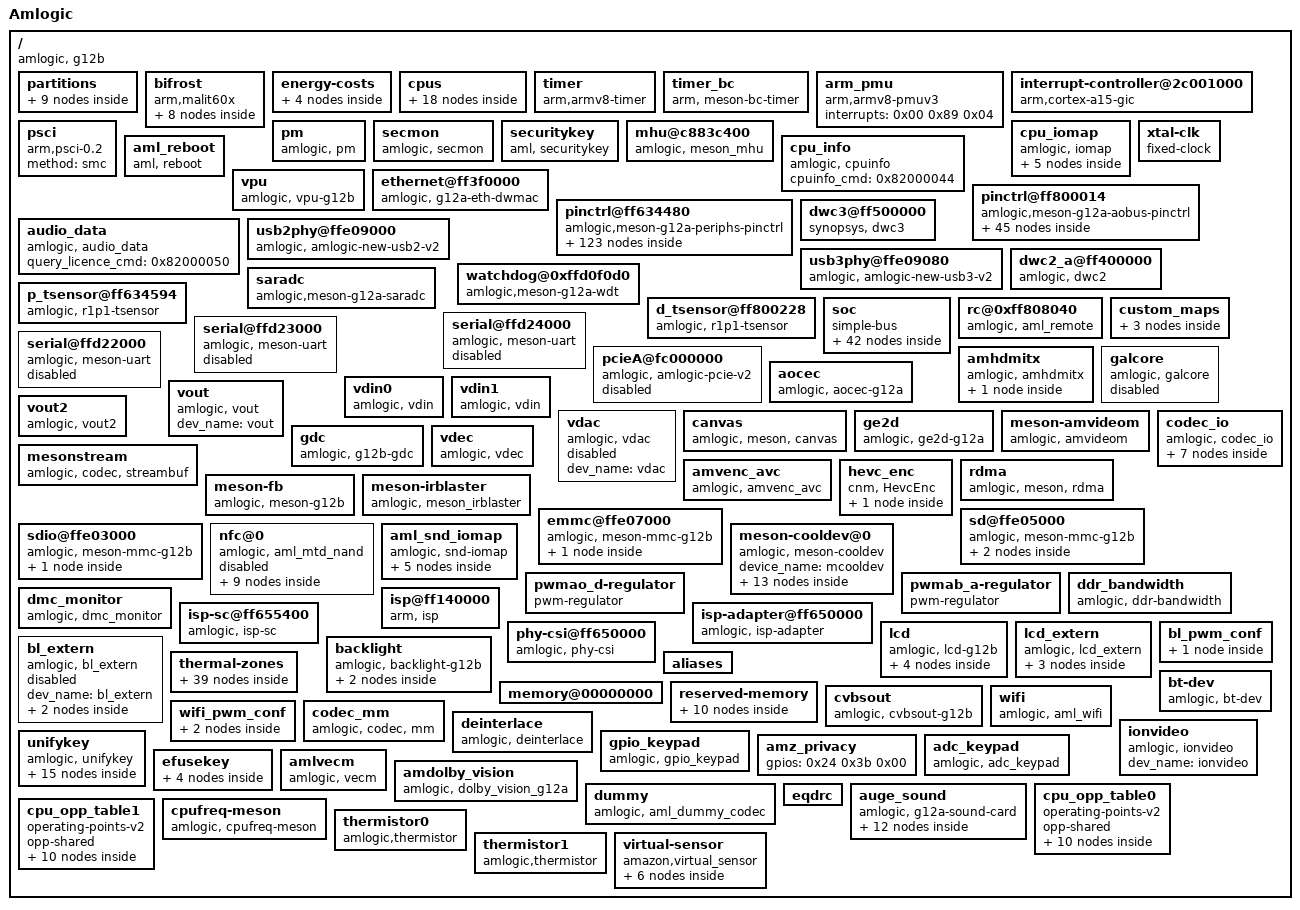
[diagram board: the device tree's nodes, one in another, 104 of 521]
/dts-v1/;

/ {
	model = "Amlogic";
	amlogic-dt-id = "g12b_ravenproto_2g";
	compatible = "amlogic, g12b";
	interrupt-parent = <0x01>;
	#address-cells = <0x02>;
	#size-cells = <0x02>;

	partitions {
		parts = <0x09>;
		part-0 = <0x02>;
		part-1 = <0x03>;
		part-2 = <0x04>;
		part-3 = <0x05>;
		part-4 = <0x06>;
		part-5 = <0x07>;
		part-6 = <0x08>;
		part-7 = <0x09>;
		part-8 = <0x0a>;

		boot {
			pname = "boot";
			size = <0x00 0x1000000>;
			mask = <0x01>;
			linux,phandle = <0x02>;
			phandle = <0x02>;
		};

		recovery {
			pname = "recovery";
			size = <0x00 0x1000000>;
			mask = <0x01>;
			linux,phandle = <0x03>;
			phandle = <0x03>;
		};

		logo {
			pname = "logo";
			size = <0x00 0x400000>;
			mask = <0x01>;
			linux,phandle = <0x04>;
			phandle = <0x04>;
		};

		tee {
			pname = "tee";
			size = <0x00 0x800000>;
			mask = <0x01>;
			linux,phandle = <0x05>;
			phandle = <0x05>;
		};

		system {
			pname = "system";
			size = <0x00 0x4b000000>;
			mask = <0x01>;
			linux,phandle = <0x06>;
			phandle = <0x06>;
		};

		misc {
			pname = "misc";
			size = <0x00 0x100000>;
			mask = <0x02>;
			linux,phandle = <0x07>;
			phandle = <0x07>;
		};

		cache {
			pname = "cache";
			size = <0x00 0x20000000>;
			mask = <0x02>;
			linux,phandle = <0x08>;
			phandle = <0x08>;
		};

		vendor {
			pname = "vendor";
			size = <0x00 0x10000000>;
			mask = <0x01>;
			linux,phandle = <0x09>;
			phandle = <0x09>;
		};

		data {
			pname = "data";
			size = <0xffffffff 0xffffffff>;
			mask = <0x04>;
			linux,phandle = <0x0a>;
			phandle = <0x0a>;
		};
	};

	bifrost {
		compatible = "arm,malit60x\0arm,malit6xx\0arm,mali-midgard";
		#cooling-cells = <0x02>;
		reg = <0x00 0xffe40000 0x00 0x4000 0x00 0xffd01000 0x00 0x1000 0x00 0xff800000 0x00 0x1000 0x00 0xff63c000 0x00 0x1000 0x00 0xffd01000 0x00 0x1000>;
		interrupt-parent = <0x01>;
		interrupts = <0x00 0xa0 0x04 0x00 0xa1 0x04 0x00 0xa2 0x04>;
		interrupt-names = "GPU\0MMU\0JOB";
		num_of_pp = <0x02>;
		sc_mpp = <0x01>;
		clocks = <0x0b 0x83 0x0b 0x07>;
		clock-names = "gpu_mux\0gp0_pll";
		tbl = <0x0c 0x0d 0x0e 0x0f 0x10 0x10>;
		system-coherency = <0x00>;

		clk125_cfg {
			clk_freq = <0x7735940>;
			clk_parent = "fclk_div4";
			clkp_freq = <0x1dcd6500>;
			clk_reg = <0xa03>;
			voltage = <0x47e>;
			keep_count = <0x05>;
			threshold = <0x1e 0x78>;
		};

		dvfs250_cfg {
			clk_freq = <0xee6b280>;
			clk_parent = "fclk_div4";
			clkp_freq = <0x1dcd6500>;
			clk_reg = <0xa01>;
			voltage = <0x47e>;
			keep_count = <0x05>;
			threshold = <0x50 0xaa>;
		};

		dvfs285_cfg {
			clk_freq = <0x1107a76d>;
			clk_parent = "fclk_div7";
			clkp_freq = <0x1107a76d>;
			clk_reg = <0xe00>;
			voltage = <0x47e>;
			keep_count = <0x05>;
			threshold = <0x64 0xbe>;
			linux,phandle = <0x0c>;
			phandle = <0x0c>;
		};

		dvfs400_cfg {
			clk_freq = <0x17d78400>;
			clk_parent = "fclk_div5";
			clkp_freq = <0x17d78400>;
			clk_reg = <0xc00>;
			voltage = <0x47e>;
			keep_count = <0x05>;
			threshold = <0x98 0xcf>;
			linux,phandle = <0x0d>;
			phandle = <0x0d>;
		};

		dvfs500_cfg {
			clk_freq = <0x1dcd6500>;
			clk_parent = "fclk_div4";
			clkp_freq = <0x1dcd6500>;
			clk_reg = <0xa00>;
			voltage = <0x47e>;
			keep_count = <0x05>;
			threshold = <0xb4 0xdc>;
			linux,phandle = <0x0e>;
			phandle = <0x0e>;
		};

		dvfs666_cfg {
			clk_freq = <0x27bc86aa>;
			clk_parent = "fclk_div3";
			clkp_freq = <0x27bc86aa>;
			clk_reg = <0x800>;
			voltage = <0x47e>;
			keep_count = <0x05>;
			threshold = <0xd2 0xec>;
			linux,phandle = <0x0f>;
			phandle = <0x0f>;
		};

		dvfs800_cfg {
			clk_freq = <0x2faf0800>;
			clk_parent = "fclk_div2p5";
			clkp_freq = <0x2faf0800>;
			clk_reg = <0x600>;
			voltage = <0x47e>;
			keep_count = <0x05>;
			threshold = <0xe6 0xff>;
			linux,phandle = <0x10>;
			phandle = <0x10>;
		};

		dvfs850_cfg {
			clk_freq = <0x326cef80>;
			clk_parent = "gp0_pll";
			clkp_freq = <0x326cef80>;
			clk_reg = <0x200>;
			voltage = <0x47e>;
			keep_count = <0x05>;
			threshold = <0xe6 0xff>;
		};
	};

	energy-costs {

		core-cost0 {
			busy-cost-data = <0x36 0x11 0x87 0x6e 0x10e 0xca 0x168 0x108 0x21c 0x18c 0x288 0x1d6 0x2f3 0x22d 0x330 0x26c 0x364 0x2bb 0x398 0x2f7>;
			idle-cost-data = <0x05 0x00 0x00>;
			linux,phandle = <0x1b>;
			phandle = <0x1b>;
		};

		core-cost1 {
			busy-cost-data = <0x21 0x04 0x53 0x17 0xa6 0x29 0xdd 0x36 0x14c 0x4e 0x18f 0x5c 0x1d1 0x0b 0x1f7 0x87 0x217 0xa2 0x237 0xb8 0x277 0x117>;
			idle-cost-data = <0x03 0x00 0x00>;
			linux,phandle = <0x17>;
			phandle = <0x17>;
		};

		cluster-cost0 {
			busy-cost-data = <0x36 0x11 0x87 0x14 0x10e 0x19 0x168 0x1b 0x21c 0x23 0x288 0x28 0x2f3 0x31 0x330 0x39 0x364 0x36 0x398 0x40>;
			idle-cost-data = <0x0a 0x0a 0x00>;
			linux,phandle = <0x1c>;
			phandle = <0x1c>;
		};

		cluster-cost1 {
			busy-cost-data = <0x21 0x07 0x53 0x08 0xa6 0x09 0xdd 0x0a 0x14c 0x0d 0x18f 0x0f 0x1d1 0x13 0x1f7 0x17 0x217 0x1a 0x237 0x1f 0x277 0x2a>;
			idle-cost-data = <0x06 0x06 0x00>;
			linux,phandle = <0x18>;
			phandle = <0x18>;
		};
	};

	cpus {
		#address-cells = <0x02>;
		#size-cells = <0x00>;

		cpu-map {

			cluster0 {

				core0 {
					cpu = <0x11>;
				};

				core1 {
					cpu = <0x12>;
				};
			};

			cluster1 {

				core0 {
					cpu = <0x13>;
				};

				core1 {
					cpu = <0x14>;
				};

				core2 {
					cpu = <0x15>;
				};

				core3 {
					cpu = <0x16>;
				};
			};
		};

		cpu@0 {
			device_type = "cpu";
			compatible = "arm,cortex-a53\0arm,armv8";
			reg = <0x00 0x00>;
			enable-method = "psci";
			sched-energy-costs = <0x17 0x18>;
			clocks = <0x0b 0x17 0x0b 0x16 0x0b 0xe7>;
			clock-names = "core_clk\0low_freq_clk_parent\0high_freq_clk_parent";
			operating-points-v2 = <0x19>;
			cpu-supply = <0x1a>;
			voltage-tolerance = <0x00>;
			clock-latency = <0xc350>;
			linux,phandle = <0x11>;
			phandle = <0x11>;
		};

		cpu@1 {
			device_type = "cpu";
			compatible = "arm,cortex-a53\0arm,armv8";
			reg = <0x00 0x01>;
			enable-method = "psci";
			sched-energy-costs = <0x17 0x18>;
			clocks = <0x0b 0x17 0x0b 0x16 0x0b 0xe7>;
			clock-names = "core_clk\0low_freq_clk_parent\0high_freq_clk_parent";
			operating-points-v2 = <0x19>;
			cpu-supply = <0x1a>;
			voltage-tolerance = <0x00>;
			clock-latency = <0xc350>;
			linux,phandle = <0x12>;
			phandle = <0x12>;
		};

		cpu@100 {
			device_type = "cpu";
			compatible = "arm,cortex-a73\0arm,armv8";
			reg = <0x00 0x100>;
			enable-method = "psci";
			sched-energy-costs = <0x1b 0x1c>;
			clocks = <0x0b 0xd7 0x0b 0xd6 0x0b 0x00>;
			clock-names = "core_clk\0low_freq_clk_parent\0high_freq_clk_parent";
			operating-points-v2 = <0x1d>;
			cpu-supply = <0x1e>;
			voltage-tolerance = <0x00>;
			clock-latency = <0xc350>;
			linux,phandle = <0x13>;
			phandle = <0x13>;
		};

		cpu@101 {
			device_type = "cpu";
			compatible = "arm,cortex-a73\0arm,armv8";
			reg = <0x00 0x101>;
			enable-method = "psci";
			sched-energy-costs = <0x1b 0x1c>;
			clocks = <0x0b 0xd7 0x0b 0xd6 0x0b 0x00>;
			clock-names = "core_clk\0low_freq_clk_parent\0high_freq_clk_parent";
			operating-points-v2 = <0x1d>;
			cpu-supply = <0x1e>;
			voltage-tolerance = <0x00>;
			clock-latency = <0xc350>;
			linux,phandle = <0x14>;
			phandle = <0x14>;
		};

		cpu@102 {
			device_type = "cpu";
			compatible = "arm,cortex-a73\0arm,armv8";
			reg = <0x00 0x102>;
			enable-method = "psci";
			sched-energy-costs = <0x1b 0x1c>;
			clocks = <0x0b 0xd7 0x0b 0xd6 0x0b 0x00>;
			clock-names = "core_clk\0low_freq_clk_parent\0high_freq_clk_parent";
			operating-points-v2 = <0x1d>;
			cpu-supply = <0x1e>;
			voltage-tolerance = <0x00>;
			clock-latency = <0xc350>;
			linux,phandle = <0x15>;
			phandle = <0x15>;
		};

		cpu@103 {
			device_type = "cpu";
			compatible = "arm,cortex-a73\0arm,armv8";
			reg = <0x00 0x103>;
			enable-method = "psci";
			sched-energy-costs = <0x1b 0x1c>;
			clocks = <0x0b 0xd7 0x0b 0xd6 0x0b 0x00>;
			clock-names = "core_clk\0low_freq_clk_parent\0high_freq_clk_parent";
			operating-points-v2 = <0x1d>;
			cpu-supply = <0x1e>;
			voltage-tolerance = <0x00>;
			clock-latency = <0xc350>;
			linux,phandle = <0x16>;
			phandle = <0x16>;
		};

		idle-states {
			entry-method = "arm,psci";

			cpu-sleep-0 {
				compatible = "arm,idle-state";
				arm,psci-suspend-param = <0x10000>;
				local-timer-stop;
				entry-latency-us = <0x1f40>;
				exit-latency-us = <0x1f40>;
				min-residency-us = <0x4e20>;
			};

			cluster-sleep-0 {
				compatible = "arm,idle-state";
				arm,psci-suspend-param = <0x1010000>;
				local-timer-stop;
				entry-latency-us = <0x2328>;
				exit-latency-us = <0x2328>;
				min-residency-us = <0x61a8>;
			};
		};
	};

	timer {
		compatible = "arm,armv8-timer";
		interrupts = <0x01 0x0d 0xff08 0x01 0x0e 0xff08 0x01 0x0b 0xff08 0x01 0x0a 0xff08>;
	};

	timer_bc {
		compatible = "arm, meson-bc-timer";
		reg = <0x00 0xffd0f190 0x00 0x04 0x00 0xffd0f194 0x00 0x04>;
		timer_name = "Meson TimerF";
		clockevent-rating = <0x12c>;
		clockevent-shift = <0x14>;
		clockevent-features = <0x23>;
		interrupts = <0x00 0x3c 0x01>;
		bit_enable = <0x10>;
		bit_mode = <0x0c>;
		bit_resolution = <0x00>;
	};

	arm_pmu {
		compatible = "arm,armv8-pmuv3";
		interrupts = <0x00 0x89 0x04>;
	};

	interrupt-controller@2c001000 {
		compatible = "arm,cortex-a15-gic\0arm,cortex-a9-gic";
		#interrupt-cells = <0x03>;
		#address-cells = <0x00>;
		interrupt-controller;
		reg = <0x00 0xffc01000 0x00 0x1000 0x00 0xffc02000 0x00 0x100>;
		interrupts = <0x01 0x09 0xf04>;
		linux,phandle = <0x01>;
		phandle = <0x01>;
	};

	psci {
		compatible = "arm,psci-0.2";
		method = "smc";
	};

	pm {
		compatible = "amlogic, pm";
		status = "okay";
		device_name = "aml_pm";
		reg = <0x00 0xff8000a8 0x00 0x04 0x00 0xff80023c 0x00 0x04>;
	};

	secmon {
		compatible = "amlogic, secmon";
		memory-region = <0x1f>;
		in_base_func = <0x82000020>;
		out_base_func = <0x82000021>;
		reserve_mem_size = <0x2300000>;
	};

	securitykey {
		compatible = "aml, securitykey";
		storage_query = <0x82000060>;
		storage_read = <0x82000061>;
		storage_write = <0x82000062>;
		storage_tell = <0x82000063>;
		storage_verify = <0x82000064>;
		storage_status = <0x82000065>;
		storage_list = <0x82000067>;
		storage_remove = <0x82000068>;
		storage_in_func = <0x82000023>;
		storage_out_func = <0x82000024>;
		storage_block_func = <0x82000025>;
		storage_size_func = <0x82000027>;
		storage_set_enctype = <0x8200006a>;
		storage_get_enctype = <0x8200006b>;
		storage_version = <0x8200006c>;
	};

	mhu@c883c400 {
		compatible = "amlogic, meson_mhu";
		reg = <0x00 0xff63c400 0x00 0x4c 0x00 0xfffe7000 0x00 0x800>;
		interrupts = <0x00 0xd1 0x01 0x00 0xd2 0x01>;
		#mbox-cells = <0x01>;
		mbox-names = "cpu_to_scp_low\0cpu_to_scp_high";
		mboxes = <0x20 0x00 0x20 0x01>;
		linux,phandle = <0x20>;
		phandle = <0x20>;
	};

	cpu_iomap {
		compatible = "amlogic, iomap";
		#address-cells = <0x02>;
		#size-cells = <0x02>;
		ranges;

		io_cbus_base {
			reg = <0x00 0xffd00000 0x00 0x26000>;
		};

		io_apb_base {
			reg = <0x00 0xffe01000 0x00 0x7f000>;
		};

		io_aobus_base {
			reg = <0x00 0xff800000 0x00 0xb000>;
		};

		io_vapb_base {
			reg = <0x00 0xff900000 0x00 0x50000>;
		};

		io_hiu_base {
			reg = <0x00 0xff63c000 0x00 0x2000>;
		};
	};

	xtal-clk {
		compatible = "fixed-clock";
		clock-frequency = <0x16e3600>;
		clock-output-names = "xtal";
		#clock-cells = <0x00>;
		linux,phandle = <0x25>;
		phandle = <0x25>;
	};

	cpu_info {
		compatible = "amlogic, cpuinfo";
		status = "okay";
		cpuinfo_cmd = <0x82000044>;
	};

	aml_reboot {
		compatible = "aml, reboot";
		sys_reset = <0x84000009>;
		sys_poweroff = <0x84000008>;
	};

	vpu {
		compatible = "amlogic, vpu-g12b";
		dev_name = "vpu";
		status = "okay";
		clocks = <0x0b 0x95 0x0b 0x4c 0x0b 0x87 0x0b 0x8b 0x0b 0x8c>;
		clock-names = "vapb_clk\0vpu_intr_gate\0vpu_clk0\0vpu_clk1\0vpu_clk";
		clk_level = <0x07>;
	};

	ethernet@ff3f0000 {
		compatible = "amlogic, g12a-eth-dwmac\0snps,dwmac";
		reg = <0x00 0xff3f0000 0x00 0x10000 0x00 0xff634540 0x00 0x08 0x00 0xff64c000 0x00 0xa0>;
		reg-names = "eth_base\0eth_cfg\0eth_pll";
		interrupts = <0x00 0x08 0x01>;
		interrupt-names = "macirq";
		status = "okay";
		clocks = <0x0b 0x38>;
		clock-names = "ethclk81";
		pll_val = <0x9c0040a 0x927e0000 0xac5f49e5>;
		analog_val = <0x20200000 0xc000 0x23>;
		pinctrl-names = "external_eth_pins";
		pinctrl-0 = <0x21>;
		mc_val = <0x1621>;
		internal_phy = <0x00>;
	};

	pinctrl@ff800014 {
		compatible = "amlogic,meson-g12a-aobus-pinctrl";
		#address-cells = <0x02>;
		#size-cells = <0x02>;
		ranges;

		ao-bank@ff800014 {
			reg = <0x00 0xff800014 0x00 0x08 0x00 0xff800024 0x00 0x14 0x00 0xff80001c 0x00 0x08>;
			reg-names = "mux\0gpio\0drive-strength";
			gpio-controller;
			#gpio-cells = <0x02>;
			linux,phandle = <0x88>;
			phandle = <0x88>;
		};

		ao_uart {

			mux {
				groups = "uart_ao_tx_a\0uart_ao_rx_a";
				function = "uart_ao_a";
			};
		};

		ao_b_uart {
			linux,phandle = <0x29>;
			phandle = <0x29>;

			mux {
				groups = "uart_ao_tx_b_2\0uart_ao_rx_b_3";
				function = "uart_ao_b";
			};
		};

		ao_i2c_pins1 {

			mux {
				groups = "i2c_ao_sck\0i2c_ao_sda";
				function = "i2c_ao";
				bias-pull-up;
				drive-strength = <0x02>;
			};
		};

		ao_i2c_pins2 {

			mux {
				groups = "i2c_ao_sck_e\0i2c_ao_sda_e";
				function = "i2c_ao";
				bias-pull-up;
				drive-strength = <0x02>;
			};
		};

		ao_i2c_slave_pins {
			linux,phandle = <0x28>;
			phandle = <0x28>;

			mux {
				groups = "i2c_ao_slave_sck\0i2c_ao_slave_sda";
				function = "i2c_ao_slave";
			};
		};

		pwm_ao_a {

			mux {
				groups = "pwm_ao_a";
				function = "pwm_ao_a";
			};
		};

		pwm_ao_a_hiz {

			mux {
				groups = "pwm_ao_a_hiz";
				function = "pwm_ao_a";
			};
		};

		pwm_ao_b {

			mux {
				groups = "pwm_ao_b";
				function = "pwm_ao_b";
			};
		};

		pwm_ao_c_pins1 {

			mux {
				groups = "pwm_ao_c_4";
				function = "pwm_ao_c";
			};
		};

		pwm_ao_c_pins2 {

			mux {
				groups = "pwm_ao_c_6";
				function = "pwm_ao_c";
			};
		};

		pwm_ao_c_hiz {

			mux {
				groups = "pwm_ao_c_hiz_4";
				function = "pwm_ao_c";
			};
		};

		pwm_ao_d_pins1 {

			mux {
				groups = "pwm_ao_d_5";
				function = "pwm_ao_d";
			};
		};

		pwm_ao_d_pins2 {

			mux {
				groups = "pwm_ao_d_10";
				function = "pwm_ao_d";
			};
		};

		pwm_ao_d_pins3 {
			linux,phandle = <0x56>;
			phandle = <0x56>;

			mux {
				groups = "pwm_ao_d_e";
				function = "pwm_ao_d";
			};
		};

		ao_ceca {

			mux {
				groups = "cec_ao_a";
				function = "cec_ao";
			};
		};

		ao_cecb {

			mux {
				groups = "cec_ao_b";
				function = "cec_ao";
			};
		};

		pwm_a_e2 {
			linux,phandle = <0x58>;
			phandle = <0x58>;

			mux {
				groups = "pwm_a_e2";
				function = "pwm_a_gpioe";
			};
		};

		sd_to_ao_uart_clr_pins {
			linux,phandle = <0x4c>;
			phandle = <0x4c>;

			mux {
				groups = "GPIOAO_0\0GPIOAO_1";
				function = "gpio_aobus";
			};
		};

		sd_to_ao_uart_pins {
			linux,phandle = <0x4e>;
			phandle = <0x4e>;

			mux {
				groups = "uart_ao_tx_a\0uart_ao_rx_a";
				function = "uart_ao_a";
				bias-pull-up;
				input-enable;
			};
		};

		remote_pin {
			linux,phandle = <0x33>;
			phandle = <0x33>;

			mux {
				groups = "remote_input_ao";
				function = "remote_input_ao";
			};
		};

		irblaster_pin {
			linux,phandle = <0x45>;
			phandle = <0x45>;

			mux {
				groups = "remote_out_ao";
				function = "remote_out_ao";
			};
		};

		irblaster_pin1 {

			mux {
				groups = "remote_out_ao9";
				function = "remote_out_ao";
			};
		};
	};

	pinctrl@ff634480 {
		compatible = "amlogic,meson-g12a-periphs-pinctrl";
		#address-cells = <0x02>;
		#size-cells = <0x02>;
		ranges;

		banks@ff6346c0 {
			reg = <0x00 0xff6346c0 0x00 0x40 0x00 0xff6344e8 0x00 0x18 0x00 0xff634520 0x00 0x18 0x00 0xff634440 0x00 0x4c 0x00 0xff634740 0x00 0x1c>;
			reg-names = "mux\0pull\0pull-enable\0gpio\0drive-strength";
			gpio-controller;
			#gpio-cells = <0x02>;
			linux,phandle = <0x24>;
			phandle = <0x24>;
		};

		emmc_clk_cmd_pins {
			linux,phandle = <0x46>;
			phandle = <0x46>;

			mux {
				groups = "emmc_clk\0emmc_cmd";
				function = "emmc";
				input-enable;
				bias-pull-up;
				drive-strength = <0x03>;
			};
		};

		emmc_conf_pull_up {
			linux,phandle = <0x47>;
			phandle = <0x47>;

			mux {
				groups = "emmc_nand_d7\0emmc_nand_d6\0emmc_nand_d5\0emmc_nand_d4\0emmc_nand_d3\0emmc_nand_d2\0emmc_nand_d1\0emmc_nand_d0\0emmc_clk\0emmc_cmd";
				function = "emmc";
				input-enable;
				bias-pull-up;
				drive-strength = <0x03>;
			};
		};

		emmc_conf_pull_done {
			linux,phandle = <0x48>;
			phandle = <0x48>;

			mux {
				groups = "emmc_nand_ds";
				function = "emmc";
				input-enable;
				bias-pull-down;
				drive-strength = <0x03>;
			};
		};

		sd_clk_cmd_pins {
			linux,phandle = <0x4a>;
			phandle = <0x4a>;

			mux {
				groups = "sdcard_cmd_c\0sdcard_clk_c";
				function = "sdcard";
				input-enable;
				bias-pull-up;
				drive-strength = <0x03>;
			};
		};

		sd_all_pins {
			linux,phandle = <0x49>;
			phandle = <0x49>;

			mux {
				groups = "sdcard_d0_c\0sdcard_d1_c\0sdcard_d2_c\0sdcard_d3_c\0sdcard_cmd_c\0sdcard_clk_c";
				function = "sdcard";
				input-enable;
				bias-pull-up;
				drive-strength = <0x03>;
			};
		};

		sd_1bit_pins {
			linux,phandle = <0x4b>;
			phandle = <0x4b>;

			mux {
				groups = "sdcard_d0_c\0sdcard_cmd_c\0sdcard_clk_c";
				function = "sdcard";
				input-enable;
				bias-pull-up;
				drive-strength = <0x03>;
			};
		};

		ao_to_sd_uart_pins {
			linux,phandle = <0x4d>;
			phandle = <0x4d>;

			mux {
				groups = "uart_ao_tx_a_c3\0uart_ao_rx_a_c2";
				function = "uart_ao_a_ee";
				bias-pull-up;
				input-enable;
			};
		};

		sdio_clk_cmd_pins {
			linux,phandle = <0x50>;
			phandle = <0x50>;

			mux {
				groups = "sdio_clk\0sdio_cmd";
				function = "sdio";
				input-enable;
				bias-pull-up;
				drive-strength = <0x03>;
			};
		};

		sdio_all_pins {
			linux,phandle = <0x4f>;
			phandle = <0x4f>;

			mux {
				groups = "sdio_d0\0sdio_d1\0sdio_d2\0sdio_d3\0sdio_clk\0sdio_cmd";
				function = "sdio";
				input-enable;
				bias-pull-up;
				drive-strength = <0x03>;
			};
		};

		all_nand_pins {
			linux,phandle = <0x51>;
			phandle = <0x51>;

			mux {
				groups = "emmc_nand_d0\0emmc_nand_d1\0emmc_nand_d2\0emmc_nand_d3\0emmc_nand_d4\0emmc_nand_d5\0emmc_nand_d6\0emmc_nand_d7\0nand_ce0\0nand_ale\0nand_cle\0nand_wen_clk\0nand_ren_wr\0nand_rb0";
				function = "nand";
				input-enable;
			};
		};

		nand_cs {
			linux,phandle = <0x52>;
			phandle = <0x52>;

			mux {
				groups = "nand_ce0";
				function = "nand";
			};
		};

		i2c0_pins1 {

			mux {
				groups = "i2c0_sda_c\0i2c0_sck_c";
				function = "i2c0";
				bias-pull-up;
				drive-strength = <0x02>;
			};
		};

		i2c0_pins2 {
			linux,phandle = <0x26>;
			phandle = <0x26>;

			mux {
				groups = "i2c0_sda_z0\0i2c0_sck_z1";
				function = "i2c0";
				bias-pull-up;
				drive-strength = <0x02>;
			};
		};

		i2c0_pins3 {

			mux {
				groups = "i2c0_sda_z7\0i2c0_sck_z8";
				function = "i2c0";
				bias-pull-up;
				drive-strength = <0x02>;
			};
		};

		i2c1_pins1 {

			mux {
				groups = "i2c1_sda_x\0i2c1_sck_x";
				function = "i2c1";
				bias-pull-up;
				drive-strength = <0x02>;
			};
		};

		i2c1_pins2 {

			mux {
				groups = "i2c1_sda_h2\0i2c1_sck_h3";
				function = "i2c1";
				bias-pull-up;
				drive-strength = <0x02>;
			};
		};

		i2c1_pins3 {

			mux {
				groups = "i2c1_sda_h6\0i2c1_sck_h7";
				function = "i2c1";
				bias-pull-up;
				drive-strength = <0x02>;
			};
		};

		i2c2_pins1 {

			mux {
				groups = "i2c2_sda_x\0i2c2_sck_x";
				function = "i2c2";
				bias-pull-up;
				drive-strength = <0x02>;
			};
		};

		i2c2_pins2 {

			mux {
				groups = "i2c2_sda_z\0i2c2_sck_z";
				function = "i2c2";
				bias-pull-up;
				drive-strength = <0x02>;
			};
		};

		i2c3_pins1 {
			linux,phandle = <0x3f>;
			phandle = <0x3f>;

			mux {
				groups = "i2c3_sda_h\0i2c3_sck_h";
				function = "i2c3";
				bias-pull-up;
				drive-strength = <0x02>;
			};
		};

		i2c3_pins2 {
			linux,phandle = <0x27>;
			phandle = <0x27>;

			mux {
				groups = "i2c3_sda_a\0i2c3_sck_a";
				function = "i2c3";
				bias-pull-up;
				drive-strength = <0x02>;
			};
		};

		pwm_a {

			mux {
				groups = "pwm_a";
				function = "pwm_a";
			};
		};

		pwm_b_pins1 {

			mux {
				groups = "pwm_b_x7";
				function = "pwm_b";
			};
		};

		pwm_b_pins2 {

			mux {
				groups = "pwm_b_x19";
				function = "pwm_b";
			};
		};

		pwm_b_pins3 {

			mux {
				groups = "pwm_b_h";
				function = "pwm_b";
			};
		};

		pwm_b_pins4 {

			mux {
				groups = "pwm_b_z0";
				function = "pwm_b";
			};
		};

		pwm_b_pins5 {

			mux {
				groups = "pwm_b_z13";
				function = "pwm_b";
			};
		};

		pwm_c_pins1 {

			mux {
				groups = "pwm_c_c4";
				function = "pwm_c";
			};
		};

		pwm_c_pins2 {

			mux {
				groups = "pwm_c_x5";
				function = "pwm_c";
			};
		};

		pwm_c_pins3 {

			mux {
				groups = "pwm_c_x8";
				function = "pwm_c";
			};
		};

		pwm_c_pins4 {

			mux {
				groups = "pwm_c_z";
				function = "pwm_c";
			};
		};

		pwm_d_pins1 {

			mux {
				groups = "pwm_d_x3";
				function = "pwm_d";
			};
		};

		pwm_d_pins2 {

			mux {
				groups = "pwm_d_x6";
				function = "pwm_d";
			};
		};

		pwm_d_pins3 {

			mux {
				groups = "pwm_d_z";
				function = "pwm_d";
			};
		};

		pwm_d_pins4 {

			mux {
				groups = "pwm_d_a4";
				function = "pwm_d";
			};
		};

		pwm_e {
			linux,phandle = <0x6e>;
			phandle = <0x6e>;

			mux {
				groups = "pwm_e";
				function = "pwm_e";
			};
		};

		pwm_f_pins1 {

			mux {
				groups = "pwm_f_x";
				function = "pwm_f";
			};
		};

		pwm_f_pins2 {
			linux,phandle = <0x5c>;
			phandle = <0x5c>;

			mux {
				groups = "pwm_f_h";
				function = "pwm_f";
			};
		};

		pwm_f_pins3 {

			mux {
				groups = "pwm_f_z";
				function = "pwm_f";
			};
		};

		pwm_f_pins4 {

			mux {
				groups = "pwm_f_a11";
				function = "pwm_f";
			};
		};

		spicc0_pins_x {

			mux {
				groups = "spi0_mosi_x\0spi0_miso_x\0spi0_clk_x";
				function = "spi0";
				drive-strength = <0x01>;
			};
		};

		spicc1_pins {

			mux {
				groups = "spi1_mosi\0spi1_miso\0spi1_clk";
				function = "spi1";
				drive-strength = <0x01>;
			};
		};

		a_uart {
			linux,phandle = <0x38>;
			phandle = <0x38>;

			mux {
				groups = "uart_tx_a\0uart_rx_a\0uart_cts_a\0uart_rts_a";
				function = "uart_a";
			};
		};

		b_uart {
			linux,phandle = <0x39>;
			phandle = <0x39>;

			mux {
				groups = "uart_tx_b\0uart_rx_b";
				function = "uart_b";
			};
		};

		c_uart {
			linux,phandle = <0x3a>;
			phandle = <0x3a>;

			mux {
				groups = "uart_tx_c\0uart_rx_c";
				function = "uart_c";
			};
		};

		hdmitx_hpd {
			linux,phandle = <0x3c>;
			phandle = <0x3c>;

			mux {
				groups = "hdmitx_hpd_in";
				function = "hdmitx";
				bias-disable;
			};
		};

		hdmitx_hpd_gpio {
			linux,phandle = <0x3e>;
			phandle = <0x3e>;

			mux {
				groups = "GPIOH_1";
				function = "gpio_periphs";
				bias-disable;
			};
		};

		hdmitx_ddc {
			linux,phandle = <0x3d>;
			phandle = <0x3d>;

			mux {
				groups = "hdmitx_sda\0hdmitx_sck";
				function = "hdmitx";
				bias-disable;
			};
		};

		ee_ceca {
			linux,phandle = <0x40>;
			phandle = <0x40>;

			mux {
				groups = "cec_ao_a_ee";
				function = "cec_ao_ee";
			};
		};

		ee_cecb {
			linux,phandle = <0x41>;
			phandle = <0x41>;

			mux {
				groups = "cec_ao_b_ee";
				function = "cec_ao_ee";
			};
		};

		internal_eth_pins {

			mux {
				groups = "eth_link_led\0eth_act_led";
				function = "eth";
			};
		};

		external_eth_pins {
			linux,phandle = <0x21>;
			phandle = <0x21>;

			mux {
				groups = "eth_mdio\0eth_mdc\0eth_rgmii_rx_clk\0eth_rx_dv\0eth_rxd0\0eth_rxd1\0eth_rxd2_rgmii\0eth_rxd3_rgmii\0eth_rgmii_tx_clk\0eth_txen\0eth_txd0\0eth_txd1\0eth_txd2_rgmii\0eth_txd3_rgmii";
				function = "eth";
				drive-strength = <0x03>;
			};
		};

		irblaster_pins2 {

			mux {
				groups = "remote_out_h";
				function = "remote_out";
			};
		};

		irblaster_pins3 {

			mux {
				groups = "remote_out_z";
				function = "remote_out";
			};
		};

		tdmout_a {
			linux,phandle = <0x2c>;
			phandle = <0x2c>;

			mux {
				groups = "tdma_sclk\0tdma_fs\0tdma_dout0";
				function = "tdma_out";
			};
		};

		tdmin_a {
			linux,phandle = <0x2d>;
			phandle = <0x2d>;

			mux {
				groups = "tdma_din1";
				function = "tdma_in";
			};
		};

		tdmb_mclk {
			linux,phandle = <0x2e>;
			phandle = <0x2e>;

			mux {
				groups = "mclk0_a";
				function = "mclk0";
				drive-strength = <0x02>;
			};
		};

		tdmout_b {
			linux,phandle = <0x2f>;
			phandle = <0x2f>;

			mux {
				groups = "tdmb_sclk\0tdmb_fs\0tdmb_dout0";
				function = "tdmb_out";
				drive-strength = <0x02>;
			};
		};

		tdmc_mclk {
			linux,phandle = <0x30>;
			phandle = <0x30>;

			mux {
				groups = "mclk1_a";
				function = "mclk1";
			};
		};

		tdmout_c {
			linux,phandle = <0x31>;
			phandle = <0x31>;

			mux {
				groups = "tdmc_sclk_a\0tdmc_fs_a";
				function = "tdmc_out";
			};
		};

		tdmin_c {
			linux,phandle = <0x32>;
			phandle = <0x32>;

			mux {
				groups = "tdmc_din0_a";
				function = "tdmc_in";
			};
		};
	};

	audio_data {
		compatible = "amlogic, audio_data";
		query_licence_cmd = <0x82000050>;
		status = "okay";
	};

	dwc3@ff500000 {
		compatible = "synopsys, dwc3";
		status = "okay";
		reg = <0x00 0xff500000 0x00 0x100000>;
		interrupts = <0x00 0x1e 0x04>;
		usb-phy = <0x22 0x23>;
		cpu-type = "gxl";
		clock-src = "usb3.0";
		clocks = <0x0b 0x41>;
		clock-names = "dwc_general";
	};

	usb2phy@ffe09000 {
		compatible = "amlogic, amlogic-new-usb2-v2";
		status = "okay";
		reg = <0x00 0xffe09000 0x00 0x80 0x00 0xffd01008 0x00 0x100 0x00 0xff636000 0x00 0x2000 0x00 0xff63a000 0x00 0x2000>;
		pll-setting-1 = <0x9400414>;
		pll-setting-2 = <0x927e0000>;
		pll-setting-3 = <0xac5f49e5>;
		pll-setting-4 = <0xfe18>;
		pll-setting-5 = <0xfff>;
		pll-setting-6 = <0xc8000>;
		pll-setting-7 = <0xe0004>;
		pll-setting-8 = <0xe000c>;
		portnum = <0x02>;
		linux,phandle = <0x22>;
		phandle = <0x22>;
	};

	usb3phy@ffe09080 {
		compatible = "amlogic, amlogic-new-usb3-v2";
		status = "okay";
		reg = <0x00 0xffe09080 0x00 0x20>;
		phy-reg = <0xff646000>;
		phy-reg-size = <0x2000>;
		usb2-phy-reg = <0xffe09000>;
		usb2-phy-reg-size = <0x80>;
		interrupts = <0x00 0x10 0x04>;
		clocks = <0x0b 0x18>;
		clock-names = "pcie_refpll";
		portnum = <0x01>;
		otg = <0x01>;
		gpio-vbus-power = "GPIOH_4";
		gpios = <0x24 0x15 0x00>;
		linux,phandle = <0x23>;
		phandle = <0x23>;
	};

	dwc2_a@ff400000 {
		compatible = "amlogic, dwc2";
		status = "okay";
		device_name = "dwc2_a";
		reg = <0x00 0xff400000 0x00 0x40000>;
		interrupts = <0x00 0x1f 0x04>;
		pl-periph-id = <0x00>;
		clock-src = "usb0";
		port-id = <0x00>;
		port-type = <0x02>;
		port-speed = <0x00>;
		port-config = <0x00>;
		port-dma = <0x00>;
		port-id-mode = <0x00>;
		usb-fifo = <0x2d8>;
		cpu-type = "v2";
		phy-reg = <0xffe09000>;
		phy-reg-size = <0xa0>;
		phy-interface = <0x00>;
		clocks = <0x0b 0x41 0x0b 0x49>;
		clock-names = "usb_general\0usb1";
		controller-type = <0x03>;
	};

	watchdog@0xffd0f0d0 {
		compatible = "amlogic,meson-g12a-wdt";
		status = "okay";
		reg = <0x00 0xffd0f0d0 0x00 0x10>;
		clock-names = "xtal";
		clocks = <0x25>;
	};

	saradc {
		compatible = "amlogic,meson-g12a-saradc";
		status = "okay";
		#io-channel-cells = <0x01>;
		clocks = <0x25 0x0b 0xeb>;
		clock-names = "xtal\0saradc_clk";
		interrupts = <0x00 0xc8 0x01>;
		reg = <0x00 0xff809000 0x00 0x48>;
		linux,phandle = <0x73>;
		phandle = <0x73>;
	};

	p_tsensor@ff634594 {
		compatible = "amlogic, r1p1-tsensor";
		device_name = "meson-pthermal";
		status = "okay";
		reg = <0x00 0xff634800 0x00 0x50 0x00 0xff800268 0x00 0x04>;
		cal_type = <0x01>;
		cal_a = <0x144>;
		cal_b = <0x1a8>;
		cal_c = <0xc57>;
		cal_d = <0x24c3>;
		rtemp = <0x1fbd0>;
		interrupts = <0x00 0x23 0x00>;
		clocks = <0x0b 0xd2>;
		clock-names = "ts_comp";
		#thermal-sensor-cells = <0x01>;
		linux,phandle = <0x5f>;
		phandle = <0x5f>;
	};

	d_tsensor@ff800228 {
		compatible = "amlogic, r1p1-tsensor";
		device_name = "meson-dthermal";
		status = "okay";
		reg = <0x00 0xff634c00 0x00 0x50 0x00 0xff800230 0x00 0x04>;
		cal_type = <0x01>;
		cal_a = <0x144>;
		cal_b = <0x1a8>;
		cal_c = <0xc57>;
		cal_d = <0x24c3>;
		rtemp = <0x1fbd0>;
		interrupts = <0x00 0x24 0x00>;
		clocks = <0x0b 0xd2>;
		clock-names = "ts_comp";
		#thermal-sensor-cells = <0x01>;
		linux,phandle = <0x67>;
		phandle = <0x67>;
	};

	soc {
		compatible = "simple-bus";
		#address-cells = <0x02>;
		#size-cells = <0x02>;
		ranges;

		cbus@ffd00000 {
			compatible = "simple-bus";
			reg = <0x00 0xffd00000 0x00 0x26000>;
			#address-cells = <0x02>;
			#size-cells = <0x02>;
			ranges = <0x00 0x00 0x00 0xffd00000 0x00 0x26000>;

			interrupt-controller@f080 {
				compatible = "amlogic,meson-gpio-intc\0amlogic,meson-g12a-gpio-intc";
				reg = <0x00 0xf080 0x00 0x10>;
				interrupt-controller;
				#interrupt-cells = <0x02>;
				amlogic,channel-interrupts = <0x40 0x41 0x42 0x43 0x44 0x45 0x46 0x47>;
				status = "okay";
			};

			meson_clk_msr {
				compatible = "amlogic, gxl_measure";
				reg = <0x00 0x18004 0x00 0x04 0x00 0x1800c 0x00 0x04>;
			};

			pwm@1b000 {
				compatible = "amlogic,g12b-ee-pwm";
				reg = <0x00 0x1b000 0x00 0x20>;
				#pwm-cells = <0x03>;
				clocks = <0x25 0x25 0x25 0x25>;
				clock-names = "clkin0\0clkin1\0clkin2\0clkin3";
				status = "okay";
				linux,phandle = <0x59>;
				phandle = <0x59>;
			};

			pwm@1a000 {
				compatible = "amlogic,g12b-ee-pwm";
				reg = <0x00 0x1a000 0x00 0x20>;
				#pwm-cells = <0x03>;
				clocks = <0x25 0x25 0x25 0x25>;
				clock-names = "clkin0\0clkin1\0clkin2\0clkin3";
				status = "disabled";
			};

			pwm@19000 {
				compatible = "amlogic,g12b-ee-pwm";
				reg = <0x00 0x19000 0x00 0x20>;
				#pwm-cells = <0x03>;
				clocks = <0x25 0x25 0x25 0x25>;
				clock-names = "clkin0\0clkin1\0clkin2\0clkin3";
				status = "okay";
				linux,phandle = <0x5e>;
				phandle = <0x5e>;
			};

			i2c@1f000 {
				compatible = "amlogic,meson-g12b-i2c";
				status = "okay";
				reg = <0x00 0x1f000 0x00 0x20>;
				interrupts = <0x00 0x15 0x01 0x00 0x5b 0x01>;
				#address-cells = <0x01>;
				#size-cells = <0x00>;
				clocks = <0x0b 0x2a>;
				clock-names = "clk_i2c";
				pinctrl-names = "default";
				pinctrl-0 = <0x26>;
				clock-frequency = <0x61a80>;

				touchscreen@5d {
					compatible = "goodix,gt9xx";
					status = "disabled";
					reg = <0x5d>;
					reset-gpio = <0x24 0x0a 0x00>;
					irq-gpio = <0x24 0x04 0x00>;
					goodix,cfg-group0 = [41 00 04 58 02 05 0c 00 02 54 07 0f 50 2d 03 05 00 00 00 00 40 00 04 20 10 f3 aa 07 28 0a 2c 2e 7c 06 00 00 00 c9 03 24 00 01 00 00 00 00 ff 5d 66 98 32 28 64 94 c5 02 08 00 00 01 91 2c 00 8a 34 00 8a 3f 00 7e 4c 00 78 5b 00 78 00 00 00 00 00 00 00 00 00 00 00 00 00 00 00 00 00 00 00 00 00 00 00 00 00 00 00 00 00 00 00 00 00 00 00 00 02 04 06 08 0a 0c 0e 10 12 14 ff ff ff ff 00 00 00 00 00 00 00 00 00 00 00 00 00 00 00 00 00 02 04 06 08 0a 0c 1d 1e 1f 20 21 22 24 26 ff ff ff ff ff ff ff ff ff ff ff 00 00 00 00 00 00 00 00 00 00 00 00 00 00 00 00 e3 01];
				};

				touchscreen@38 {
					compatible = "focaltech,fts";
					status = "disabled";
					reg = <0x38>;
					reset-gpio = <0x24 0x0a 0x00>;
					irq-gpio = <0x24 0x04 0x00>;
					x_max = <0x2d0>;
					y_max = <0x500>;
					max-touch-number = <0x0a>;
				};
			};

			i2c@1e000 {
				compatible = "amlogic,meson-g12b-i2c";
				status = "disabled";
				reg = <0x00 0x1e000 0x00 0x20>;
				interrupts = <0x00 0xd6 0x01 0x00 0x5c 0x01>;
				#address-cells = <0x01>;
				#size-cells = <0x00>;
				clocks = <0x0b 0x2a>;
				clock-names = "clk_i2c";
			};

			i2c@1d000 {
				compatible = "amlogic,meson-g12b-i2c";
				status = "disabled";
				reg = <0x00 0x1d000 0x00 0x20>;
				interrupts = <0x00 0xd7 0x01 0x00 0x5e 0x01>;
				#address-cells = <0x01>;
				#size-cells = <0x00>;
				clocks = <0x0b 0x2a>;
				clock-names = "clk_i2c";
			};

			i2c@1c000 {
				compatible = "amlogic,meson-g12b-i2c";
				status = "okay";
				reg = <0x00 0x1c000 0x00 0x20>;
				interrupts = <0x00 0x27 0x01 0x00 0x5f 0x01>;
				#address-cells = <0x01>;
				#size-cells = <0x00>;
				clocks = <0x0b 0x2a>;
				clock-names = "clk_i2c";
				pinctrl-names = "default";
				pinctrl-0 = <0x27>;
				clock-frequency = <0x186a0>;

				is31fl3236@3F {
					compatible = "issi,is31fl3236";
					reg = <0x3f>;
					play-boot-animation;
					enable-gpio = <0x24 0x36 0x00>;
					buck-gpio = <0x24 0x28 0x00>;
					channel-offset = [0c];
					setup-device;
				};

				tlv320dac3203@30 {
					compatible = "ti, tlv320dac3203";
					#sound-dai-cells = <0x00>;
					reg = <0x18>;
					status = "okay";
					reset_pin = <0x24 0x3a 0x00>;
				};

				tsl2540@39 {
					compatible = "amstaos,tsl2540";
					reg = <0x39>;
					als_name = "taos_als";
					persist = <0x12>;
					als_gain = <0x03>;
					als_gain_factor = <0x01>;
					als_deltap = <0x0a>;
					als_time = <0x7b>;
					d_factor = <0xfa2f>;
					ch0_coef0 = <0x3e8>;
					ch1_coef0 = <0x156>;
					ch0_coef1 = <0x28>;
					ch1_coef1 = <0x00>;
					az_iterations = <0x7e>;
					als_can_wake = <0x00>;
					boot-on;
					#address-cells = <0x01>;
					#size-cells = <0x01>;
					status = "okay";
				};

				bl_extern_i2c {
					compatible = "amlogic, bl_extern_i2c";
					status = "disabled";
					reg = <0x2c>;
					dev_name = "lp8556";
				};
			};

			spi@13000 {
				compatible = "amlogic,meson-g12b-spicc\0amlogic,meson-g12a-spicc";
				reg = <0x00 0x13000 0x00 0x44>;
				interrupts = <0x00 0x51 0x04>;
				clocks = <0x0b 0x29 0x0b 0xcd>;
				clock-names = "core\0comp";
				#address-cells = <0x01>;
				#size-cells = <0x00>;
				status = "disabled";
			};

			spi@15000 {
				compatible = "amlogic,meson-g12b-spicc\0amlogic,meson-g12a-spicc";
				reg = <0x00 0x15000 0x00 0x44>;
				interrupts = <0x00 0x5a 0x04>;
				clocks = <0x0b 0x2f 0x0b 0xd1>;
				clock-names = "core\0comp";
				#address-cells = <0x01>;
				#size-cells = <0x00>;
				status = "disabled";
			};
		};

		aobus@ff800000 {
			compatible = "simple-bus";
			reg = <0x00 0xff800000 0x00 0xb000>;
			#address-cells = <0x02>;
			#size-cells = <0x02>;
			ranges = <0x00 0x00 0x00 0xff800000 0x00 0xb000>;

			cpu_version {
				reg = <0x00 0x220 0x00 0x04>;
			};

			clock-controller@0 {
				compatible = "amlogic,g12b-aoclkc";
				#clock-cells = <0x01>;
				reg = <0x00 0x00 0x00 0x320>;
			};

			pwm@7000 {
				compatible = "amlogic,g12b-ao-pwm";
				reg = <0x00 0x7000 0x00 0x20>;
				#pwm-cells = <0x03>;
				clocks = <0x25 0x25 0x25 0x25>;
				clock-names = "clkin0\0clkin1\0clkin2\0clkin3";
				status = "disabled";
			};

			pwm@2000 {
				compatible = "amlogic,g12b-ao-pwm";
				reg = <0x00 0x2000 0x00 0x20>;
				#pwm-cells = <0x03>;
				clocks = <0x25 0x25 0x25 0x25>;
				clock-names = "clkin0\0clkin1\0clkin2\0clkin3";
				status = "okay";
				linux,phandle = <0x57>;
				phandle = <0x57>;
			};

			i2c@5000 {
				compatible = "amlogic,meson-g12b-i2c";
				status = "disabled";
				reg = <0x00 0x5000 0x00 0x20>;
				interrupts = <0x00 0xc3 0x01 0x00 0xc9 0x01>;
				#address-cells = <0x01>;
				#size-cells = <0x00>;
				clocks = <0x0b 0x2a>;
				clock-names = "clk_i2c";
			};

			i2c_slave@6000 {
				compatible = "amlogic, meson-i2c-slave";
				status = "disabled";
				reg = <0x00 0x6000 0x00 0x20>;
				interrupts = <0x00 0xc2 0x01>;
				pinctrl-names = "default";
				pinctrl-0 = <0x28>;
			};

			serial@3000 {
				compatible = "amlogic, meson-uart";
				reg = <0x00 0x3000 0x00 0x18>;
				interrupts = <0x00 0xc1 0x01>;
				status = "okay";
				clocks = <0x25>;
				clock-names = "clk_uart";
				xtal_tick_en = <0x02>;
				fifosize = <0x40>;
				pinctrl-names = "default";
				support-sysrq = <0x00>;
			};

			serial@4000 {
				compatible = "amlogic, meson-uart";
				reg = <0x00 0x4000 0x00 0x18>;
				interrupts = <0x00 0xc5 0x01>;
				status = "disabled";
				clocks = <0x25>;
				clock-names = "clk_uart";
				fifosize = <0x40>;
				pinctrl-names = "default";
				pinctrl-0 = <0x29>;
			};
		};

		periphs@ff634400 {
			compatible = "simple-bus";
			reg = <0x00 0xff634400 0x00 0x400>;
			#address-cells = <0x02>;
			#size-cells = <0x02>;
			ranges = <0x00 0x00 0x00 0xff634400 0x00 0x400>;
		};

		hiubus@ff63c000 {
			compatible = "simple-bus";
			reg = <0x00 0xff63c000 0x00 0x2000>;
			#address-cells = <0x02>;
			#size-cells = <0x02>;
			ranges = <0x00 0x00 0x00 0xff63c000 0x00 0x2000>;

			clock-controller@0 {
				compatible = "amlogic,g12b-clkc-1";
				#clock-cells = <0x01>;
				reg = <0x00 0x00 0x00 0x3dc>;
				linux,phandle = <0x0b>;
				phandle = <0x0b>;
			};

			clock-controller@1 {
				compatible = "amlogic,g12b-clkc-2";
				#clock-cells = <0x01>;
				reg = <0x00 0x00 0x00 0x3dc>;
			};
		};

		ion_dev {
			compatible = "amlogic, ion_dev";
			memory-region = <0x2a>;
		};

		audiobus@0xff642000 {
			compatible = "amlogic, audio-controller\0simple-bus";
			reg = <0x00 0xff642000 0x00 0x2000>;
			#address-cells = <0x02>;
			#size-cells = <0x02>;
			ranges = <0x00 0x00 0x00 0xff642000 0x00 0x2000>;

			audio_clocks {
				compatible = "amlogic, g12a-audio-clocks";
				#clock-cells = <0x01>;
				reg = <0x00 0x00 0x00 0xb0>;
				linux,phandle = <0x2b>;
				phandle = <0x2b>;
			};

			ddr_manager {
				compatible = "amlogic, g12a-audio-ddr-manager";
				interrupts = <0x00 0x94 0x01 0x00 0x95 0x01 0x00 0x96 0x01 0x00 0x98 0x01 0x00 0x99 0x01 0x00 0x9a 0x01>;
				interrupt-names = "toddr_a\0toddr_b\0toddr_c\0frddr_a\0frddr_b\0frddr_c";
			};

			tdma {
				compatible = "amlogic, g12a-snd-tdma";
				#sound-dai-cells = <0x00>;
				dai-tdm-lane-slot-mask-in = <0x00 0x01>;
				dai-tdm-oe-lane-slot-mask-out = <0x01 0x00>;
				dai-tdm-clk-sel = <0x00>;
				clocks = <0x2b 0x17 0x0b 0x0c>;
				clock-names = "mclk\0clk_srcpll";
				pinctrl-names = "tdm_pins";
				pinctrl-0 = <0x2c 0x2d>;
				linux,phandle = <0x8a>;
				phandle = <0x8a>;
			};

			tdmb {
				compatible = "amlogic, g12a-snd-tdmb";
				#sound-dai-cells = <0x00>;
				#dai-tdm-lane-slot-mask-in = <0x00 0x01 0x00 0x00>;
				dai-tdm-lane-slot-mask-out = <0x01 0x00 0x00 0x00>;
				dai-tdm-clk-sel = <0x01>;
				clocks = <0x2b 0x18 0x0b 0x0d 0x0b 0x0c>;
				clock-names = "mclk\0clk_srcpll\0samesource_sysclk";
				pinctrl-names = "tdm_pins";
				pinctrl-0 = <0x2e 0x2f>;
				samesource_sel = <0x04>;
				linux,phandle = <0x8c>;
				phandle = <0x8c>;
			};

			tdmc {
				compatible = "amlogic, g12a-snd-tdmc";
				#sound-dai-cells = <0x00>;
				dai-tdm-lane-slot-mask-in = <0x01 0x00 0x00 0x00>;
				#dai-tdm-lane-slot-mask-out = <0x01 0x00 0x01 0x01>;
				#dai-tdm-lane-oe-slot-mask-in = <0x00 0x00 0x00 0x00>;
				#dai-tdm-lane-oe-slot-mask-out = <0x01 0x00 0x00 0x00>;
				dai-tdm-clk-sel = <0x02>;
				clocks = <0x2b 0x19 0x0b 0x0e>;
				clock-names = "mclk\0clk_srcpll";
				pinctrl-names = "tdm_pins";
				pinctrl-0 = <0x30 0x31 0x32>;
				linux,phandle = <0x8e>;
				phandle = <0x8e>;
			};

			spdif_b {
				compatible = "amlogic, g12a-snd-spdif-b";
				#sound-dai-cells = <0x00>;
				clocks = <0x0b 0x0c 0x2b 0x15 0x2b 0x21>;
				clock-names = "sysclk\0gate_spdifout\0clk_spdifout";
				status = "okay";
				linux,phandle = <0x8f>;
				phandle = <0x8f>;
			};

			loopback {
				compatible = "amlogic, snd-loopback";
				lb_mode = <0x00>;
				datain_src = <0x04>;
				datain_chnum = <0x08>;
				datain_chmask = <0x3f>;
				datalb_src = <0x02>;
				datalb_chnum = <0x08>;
				datalb_chmask = <0x03>;
				status = "okay";
				linux,phandle = <0x87>;
				phandle = <0x87>;
			};

			resample {
				compatible = "amlogic, g12a-resample";
				clocks = <0x0b 0x0f 0x2b 0x1c 0x2b 0x24>;
				clock-names = "resample_pll\0resample_src\0resample_clk";
				resample_module = <0x04>;
				status = "disabled";
			};

			pwrdet {
				compatible = "amlogic, g12a-power-detect";
				interrupts = <0x00 0x9b 0x01>;
				interrupt-names = "pwrdet_irq";
				pwrdet_src = <0x04>;
				hi_th = <0x70000>;
				lo_th = <0x16000>;
				status = "disabled";
			};
		};
	};

	rc@0xff808040 {
		compatible = "amlogic, aml_remote";
		dev_name = "meson-remote";
		reg = <0x00 0xff808040 0x00 0x44 0x00 0xff808000 0x00 0x20>;
		status = "okay";
		protocol = <0x01>;
		interrupts = <0x00 0xc4 0x01>;
		pinctrl-names = "default";
		pinctrl-0 = <0x33>;
		map = <0x34>;
		max_frame_time = <0xc8>;
	};

	custom_maps {
		mapnum = <0x03>;
		map0 = <0x35>;
		map1 = <0x36>;
		map2 = <0x37>;
		linux,phandle = <0x34>;
		phandle = <0x34>;

		map_0 {
			mapname = "amlogic-remote-1";
			customcode = <0xfb04>;
			release_delay = <0x50>;
			size = <0x32>;
			keymap = <0x47000b 0x130002 0x100003 0x110004 0xf0005 0xc0006 0xd0007 0xb0008 0x80009 0x9000a 0x5c0061 0x51003d 0x50003e 0x40003f 0x4d0040 0x430041 0x170042 0x43 0x10044 0x160057 0x49000e 0x60082 0x140083 0x440067 0x1d006c 0x1c0069 0x48006a 0x53007d 0x450068 0x19006d 0x520077 0x5007a 0x59007b 0x1b0078 0x40079 0x1a0074 0xa000f 0xe0071 0x1f0066 0x1e0084 0x70085 0x120086 0x540087 0x20088 0x4f001e 0x420030 0x5d002e 0x4c0020 0x580089 0x55008c>;
			linux,phandle = <0x35>;
			phandle = <0x35>;
		};

		map_1 {
			mapname = "amlogic-remote-2";
			customcode = <0xfe01>;
			release_delay = <0x50>;
			size = <0x35>;
			keymap = <0x10002 0x20003 0x30004 0x40005 0x50006 0x60007 0x70008 0x80009 0x9000a 0xa000b 0x1f01d2 0x15008b 0x16000f 0xc0192 0xd0193 0xe0073 0xf0072 0x110066 0x1c006a 0x1b0069 0x190067 0x1a006c 0x1d001c 0x170071 0x4900db 0x43009e 0x1201d5 0x1401d6 0x1801d7 0x590166 0x5a00a6 0x100074 0x4200a5 0x4400a3 0x1e00a8 0x4b00d0 0x5800a4 0x460082 0x400083 0x380046 0x5701d0 0x5b01d1 0x54018e 0x4c018f 0x4e0190 0x550191 0x5300ed 0x5200ee 0x3900d4 0x4100d5 0xb00d6 0xd8 0x1300d9>;
			linux,phandle = <0x36>;
			phandle = <0x36>;
		};

		map_2 {
			mapname = "amlogic-remote-3";
			customcode = <0xbd02>;
			release_delay = <0x50>;
			size = <0x11>;
			keymap = <0xca0067 0xd2006c 0x990069 0xc1006a 0xce0061 0x450074 0xc50085 0x800071 0xd0000f 0xd6007d 0x950066 0xdd0068 0x8c006d 0x890083 0x9c0082 0x9a0078 0xcd0079>;
			linux,phandle = <0x37>;
			phandle = <0x37>;
		};
	};

	serial@ffd24000 {
		compatible = "amlogic, meson-uart";
		reg = <0x00 0xffd24000 0x00 0x18>;
		interrupts = <0x00 0x1a 0x01>;
		status = "disabled";
		clocks = <0x25 0x0b 0x2e>;
		clock-names = "clk_uart\0clk_gate";
		fifosize = <0x80>;
		pinctrl-names = "default";
		pinctrl-0 = <0x38>;
	};

	serial@ffd23000 {
		compatible = "amlogic, meson-uart";
		reg = <0x00 0xffd23000 0x00 0x18>;
		interrupts = <0x00 0x4b 0x01>;
		status = "disabled";
		clocks = <0x25 0x0b 0x3c>;
		clock-names = "clk_uart\0clk_gate";
		fifosize = <0x40>;
		pinctrl-names = "default";
		pinctrl-0 = <0x39>;
	};

	serial@ffd22000 {
		compatible = "amlogic, meson-uart";
		reg = <0x00 0xffd22000 0x00 0x18>;
		interrupts = <0x00 0x5d 0x01>;
		status = "disabled";
		clocks = <0x25 0x0b 0x3c>;
		clock-names = "clk_uart\0clk_gate";
		fifosize = <0x40>;
		pinctrl-names = "default";
		pinctrl-0 = <0x3a>;
	};

	pcieA@fc000000 {
		compatible = "amlogic, amlogic-pcie-v2\0snps,dw-pcie";
		reg = <0x00 0xfc000000 0x00 0x400000 0x00 0xff648000 0x00 0x2000 0x00 0xfc400000 0x00 0x200000 0x00 0xff646000 0x00 0x2000 0x00 0xffd01080 0x00 0x10>;
		reg-names = "elbi\0cfg\0config\0phy\0reset";
		interrupts = <0x00 0xdd 0x00>;
		#interrupt-cells = <0x01>;
		bus-range = <0x00 0xff>;
		#address-cells = <0x03>;
		#size-cells = <0x02>;
		interrupt-map-mask = <0x00 0x00 0x00 0x00>;
		interrupt-map = <0x00 0x00 0x00 0x00 0x01 0x00 0xdf 0x01>;
		device_type = "pci";
		ranges = <0x81000000 0x00 0x00 0x00 0xfc600000 0x00 0x100000 0x82000000 0x00 0xfc700000 0x00 0xfc700000 0x00 0x1900000>;
		num-lanes = <0x01>;
		pcie-num = <0x01>;
		clocks = <0x0b 0x18 0x0b 0x3f 0x0b 0x42>;
		clock-names = "pcie_refpll\0pcie\0pcie_phy";
		gpio-type = <0x02>;
		pcie-apb-rst-bit = <0x0f>;
		pcie-phy-rst-bit = <0x0e>;
		pcie-ctrl-a-rst-bit = <0x0c>;
		status = "disabled";
	};

	amhdmitx {
		compatible = "amlogic, amhdmitx";
		dev_name = "amhdmitx";
		status = "okay";
		vend-data = <0x3b>;
		pinctrl-names = "default\0hdmitx_i2c";
		pinctrl-0 = <0x3c 0x3d>;
		pinctrl-1 = <0x3e 0x3f>;
		clocks = <0x0b 0x55 0x0b 0x4e 0x0b 0x4f 0x0b 0x95 0x0b 0x8c>;
		clock-names = "venci_top_gate\0venci_0_gate\0venci_1_gate\0hdmi_vapb_clk\0hdmi_vpu_clk";
		interrupts = <0x00 0x39 0x01>;
		interrupt-names = "hdmitx_hpd";
		ic_type = <0x0b>;

		vend_data {
			vendor_name = "Amlogic";
			vendor_id = <0x00>;
			linux,phandle = <0x3b>;
			phandle = <0x3b>;
		};
	};

	galcore {
		compatible = "amlogic, galcore";
		dev_name = "galcore";
		status = "disabled";
		clocks = <0x0b 0xe1 0x0b 0xe0>;
		clock-names = "cts_vipnanoq_axi_clk_composite\0cts_vipnanoq_core_clk_composite";
		interrupts = <0x00 0x93 0x01>;
		interrupt-names = "galcore";
		reg = <0x00 0xff100000 0x00 0x800 0x00 0xff000000 0x00 0x400000>;
	};

	aocec {
		compatible = "amlogic, aocec-g12a";
		device_name = "aocec";
		status = "okay";
		vendor_name = "Amlogic";
		vendor_id = <0x00>;
		product_desc = "G12B";
		cec_osd_string = "AML_MBOX";
		port_num = <0x01>;
		ee_cec;
		arc_port_mask = <0x02>;
		interrupts = <0x00 0xcb 0x01 0x00 0xc7 0x01>;
		interrupt-names = "hdmi_aocecb\0hdmi_aocec";
		pinctrl-names = "default\0hdmitx_aocecb\0cec_pin_sleep";
		pinctrl-0 = <0x40>;
		pinctrl-1 = <0x41>;
		pinctrl-2 = <0x41>;
		reg = <0x00 0xff80023c 0x00 0x04 0x00 0xff800000 0x00 0x400 0x00 0xff634400 0x00 0x26>;
		reg-names = "ao_exit\0ao\0periphs";
	};

	vdin0 {
		compatible = "amlogic, vdin";
		dev_name = "vdin0";
		status = "okay";
		reserve-iomap = "true";
		flag_cma = <0x00>;
		interrupts = <0x00 0x53 0x01>;
		rdma-irq = <0x02>;
		vdin_id = <0x00>;
		memory-region = <0x42>;
		tv_bit_mode = <0x15>;
	};

	vdin1 {
		compatible = "amlogic, vdin";
		dev_name = "vdin1";
		status = "okay";
		reserve-iomap = "true";
		flag_cma = <0x00>;
		interrupts = <0x00 0x55 0x01>;
		rdma-irq = <0x04>;
		vdin_id = <0x01>;
		memory-region = <0x43>;
		tv_bit_mode = <0x01>;
	};

	vout {
		compatible = "amlogic, vout";
		dev_name = "vout";
		status = "okay";
	};

	vout2 {
		compatible = "amlogic, vout2";
		dev_name = "vout";
		status = "okay";
		clocks = <0x0b 0xc4 0x0b 0xc9>;
		clock-names = "vpu_clkc0\0vpu_clkc";
	};

	vdac {
		compatible = "amlogic, vdac";
		dev_name = "vdac";
		status = "disabled";
	};

	canvas {
		compatible = "amlogic, meson, canvas";
		dev_name = "amlogic-canvas";
		status = "okay";
		reg = <0x00 0xff638000 0x00 0x2000>;
	};

	ge2d {
		compatible = "amlogic, ge2d-g12a";
		dev_name = "ge2d";
		status = "okay";
		interrupts = <0x00 0x92 0x01>;
		interrupt-names = "ge2d";
		clocks = <0x0b 0x95 0x0b 0x3d 0x0b 0x96>;
		clock-names = "clk_vapb_0\0clk_ge2d\0clk_ge2d_gate";
		reg = <0x00 0xff940000 0x00 0x10000>;
	};

	meson-amvideom {
		compatible = "amlogic, amvideom";
		dev_name = "amvideom";
		status = "okay";
		interrupts = <0x00 0x03 0x01>;
		interrupt-names = "vsync";
	};

	codec_io {
		compatible = "amlogic, codec_io";
		status = "okay";
		#address-cells = <0x02>;
		#size-cells = <0x02>;
		ranges;

		io_cbus_base {
			reg = <0x00 0xffd00000 0x00 0x100000>;
		};

		io_dos_base {
			reg = <0x00 0xff620000 0x00 0x10000>;
		};

		io_hiubus_base {
			reg = <0x00 0xff63c000 0x00 0x2000>;
		};

		io_aobus_base {
			reg = <0x00 0xff800000 0x00 0x10000>;
		};

		io_vcbus_base {
			reg = <0x00 0xff900000 0x00 0x40000>;
		};

		io_dmc_base {
			reg = <0x00 0xff638000 0x00 0x2000>;
		};

		io_efuse_base {
			reg = <0x00 0xff630000 0x00 0x2000>;
		};
	};

	gdc {
		#address-cells = <0x02>;
		#size-cells = <0x02>;
		status = "ok";
		compatible = "amlogic, g12b-gdc";
		reg = <0x00 0xff950000 0x00 0x100 0x00 0xff63c16c 0x00 0x04 0x00 0xff63c100 0x00 0x04>;
		interrupts = <0x00 0x90 0x01>;
		interrupt-names = "GDC";
		clocks = <0x0b 0xde 0x0b 0xdf>;
		clock-names = "core\0axi";
	};

	mesonstream {
		compatible = "amlogic, codec, streambuf";
		dev_name = "mesonstream";
		status = "okay";
		clocks = <0x0b 0x40 0x0b 0x39 0x0b 0x43 0x0b 0x22 0x0b 0xa5 0x0b 0xae 0x0b 0xb7 0x0b 0xc0>;
		clock-names = "parser_top\0demux\0ahbarb0\0vdec\0clk_vdec_mux\0clk_hcodec_mux\0clk_hevc_mux\0clk_hevcb_mux";
	};

	vdec {
		compatible = "amlogic, vdec";
		dev_name = "vdec.0";
		status = "okay";
		interrupts = <0x00 0x03 0x01 0x00 0x17 0x01 0x00 0x20 0x01 0x00 0x2b 0x01 0x00 0x2c 0x01 0x00 0x2d 0x01>;
		interrupt-names = "vsync\0demux\0parser\0mailbox_0\0mailbox_1\0mailbox_2";
	};

	amvenc_avc {
		compatible = "amlogic, amvenc_avc";
		dev_name = "amvenc_avc";
		status = "okay";
		interrupts = <0x00 0x2d 0x01>;
		interrupt-names = "mailbox_2";
	};

	hevc_enc {
		compatible = "cnm, HevcEnc";
		dev_name = "HevcEnc";
		status = "okay";
		interrupts = <0x00 0xbb 0x01>;
		interrupt-names = "wave420l_irq";
		#address-cells = <0x02>;
		#size-cells = <0x02>;
		ranges;

		io_reg_base {
			reg = <0x00 0xff610000 0x00 0x4000>;
		};
	};

	rdma {
		compatible = "amlogic, meson, rdma";
		dev_name = "amlogic-rdma";
		status = "okay";
		interrupts = <0x00 0x59 0x01>;
		interrupt-names = "rdma";
	};

	meson-fb {
		compatible = "amlogic, meson-g12b";
		memory-region = <0x44>;
		dev_name = "meson-fb";
		status = "okay";
		interrupts = <0x00 0x03 0x01 0x00 0x38 0x01 0x00 0x59 0x01>;
		interrupt-names = "viu-vsync\0viu2-vsync\0rdma";
		display_mode_default = "1080p60hz";
		scale_mode = <0x01>;
		display_size_default = <0x780 0x438 0x780 0x870 0x20>;
		clocks = <0x0b 0xc9>;
		clock-names = "vpu_clkc";
		mem_size = <0x800000 0x1980000 0x100000 0x100000 0x800000>;
		logo_addr = "0x7f800000";
		mem_alloc = <0x00>;
		pxp_mode = <0x00>;
	};

	meson-irblaster {
		compatible = "amlogic, meson_irblaster";
		dev_name = "irblaster";
		reg = <0x00 0xff80014c 0x00 0x10 0x00 0xff800040 0x00 0x04>;
		pinctrl-names = "default";
		pinctrl-0 = <0x45>;
		enable_pin = <0x24 0x16 0x00>;
		interrupts = <0x00 0xc6 0x01>;
		status = "okay";
	};

	emmc@ffe07000 {
		status = "okay";
		compatible = "amlogic, meson-mmc-g12b";
		reg = <0x00 0xffe07000 0x00 0x800>;
		interrupts = <0x00 0xbf 0x01>;
		pinctrl-names = "emmc_clk_cmd_pins\0emmc_all_pins";
		pinctrl-0 = <0x46>;
		pinctrl-1 = <0x47 0x48>;
		clocks = <0x0b 0x35 0x0b 0x72 0x0b 0x02 0x0b 0x05 0x25>;
		clock-names = "core\0clkin0\0clkin1\0clkin2\0xtal";
		bus-width = <0x08>;
		cap-sd-highspeed;
		cap-mmc-highspeed;
		max-frequency = <0xbebc200>;
		non-removable;
		disable-wp;

		emmc {
			pinname = "emmc";
			ocr_avail = <0x200080>;
			tx_delay = <0x00>;
			max_req_size = <0x20000>;
			gpio_dat3 = <0x24 0x1d 0x00>;
			hw_reset = <0x24 0x23 0x00>;
			card_type = <0x01>;
			caps = "MMC_CAP_8_BIT_DATA\0MMC_CAP_MMC_HIGHSPEED\0MMC_CAP_SD_HIGHSPEED\0MMC_CAP_NONREMOVABLE\0MMC_CAP_1_8V_DDR\0MMC_CAP_HW_RESET\0MMC_CAP_ERASE\0MMC_CAP_CMD23";
			caps2 = "MMC_CAP2_HS200\0MMC_CAP2_HS400";
			f_min = <0x61a80>;
			f_max = <0xa037a00>;
		};
	};

	sd@ffe05000 {
		status = "okay";
		compatible = "amlogic, meson-mmc-g12b";
		reg = <0x00 0xffe05000 0x00 0x800>;
		interrupts = <0x00 0xbe 0x04>;
		pinctrl-names = "sd_all_pins\0sd_clk_cmd_pins\0sd_1bit_pins\0sd_clk_cmd_uart_pins\0sd_1bit_uart_pins\0sd_to_ao_uart_pins\0ao_to_sd_uart_pins\0sd_to_ao_jtag_pins\0ao_to_sd_jtag_pins";
		pinctrl-0 = <0x49>;
		pinctrl-1 = <0x4a>;
		pinctrl-2 = <0x4b>;
		pinctrl-3 = <0x4c 0x4a 0x4d>;
		pinctrl-4 = <0x4c 0x4b 0x4d>;
		pinctrl-5 = <0x49 0x4e>;
		pinctrl-6 = <0x4c 0x4d>;
		pinctrl-7 = <0x49 0x4e>;
		pinctrl-8 = <0x4c 0x4d>;
		clocks = <0x0b 0x34 0x0b 0x6e 0x0b 0x02 0x0b 0x05 0x25>;
		clock-names = "core\0clkin0\0clkin1\0clkin2\0xtal";
		bus-width = <0x04>;
		cap-sd-highspeed;
		cap-mmc-highspeed;
		max-frequency = <0x5f5e100>;
		disable-wp;

		sd {
			pinname = "sd";
			ocr_avail = <0x200080>;
			max_req_size = <0x20000>;
			gpio_dat3 = <0x24 0x2d 0x00>;
			jtag_pin = <0x24 0x2a 0x00>;
			gpio_cd = <0x24 0x30 0x00>;
			card_type = <0x05>;
			caps = "MMC_CAP_4_BIT_DATA\0MMC_CAP_MMC_HIGHSPEED\0MMC_CAP_SD_HIGHSPEED\0MMC_CAP_UHS_SDR12\0MMC_CAP_UHS_SDR25\0MMC_CAP_UHS_SDR50\0MMC_CAP_UHS_SDR104";
			vol_switch_def = <0x24 0x53 0x00>;
			vol_switch = <0x24 0x55 0x00>;
			vol_switch_delay = <0x96>;
			f_min = <0x61a80>;
			f_max = <0xbebc200>;
		};

		sdio {
			caps = "MMC_CAP_4_BIT_DATA\0MMC_CAP_MMC_HIGHSPEED\0MMC_CAP_SD_HIGHSPEED\0MMC_CAP_NONREMOVABLE\0MMC_CAP_UHS_SDR12\0MMC_CAP_UHS_SDR25\0MMC_CAP_UHS_SDR50\0MMC_CAP_UHS_SDR104\0MMC_PM_KEEP_POWER\0MMC_CAP_SDIO_IRQ";
			f_min = <0x61a80>;
			f_max = <0xbebc200>;
		};
	};

	sdio@ffe03000 {
		status = "okay";
		compatible = "amlogic, meson-mmc-g12b";
		reg = <0x00 0xffe03000 0x00 0x800>;
		interrupts = <0x00 0xbd 0x04>;
		pinctrl-names = "sdio_all_pins\0sdio_clk_cmd_pins";
		pinctrl-0 = <0x4f>;
		pinctrl-1 = <0x50>;
		clocks = <0x0b 0x33 0x0b 0x6a 0x0b 0x02 0x0b 0x05 0x25>;
		clock-names = "core\0clkin0\0clkin1\0clkin2\0xtal";
		bus-width = <0x04>;
		cap-sd-highspeed;
		cap-mmc-highspeed;
		max-frequency = <0x5f5e100>;
		disable-wp;

		sdio {
			pinname = "sdio";
			ocr_avail = <0x200080>;
			max_req_size = <0x20000>;
			card_type = <0x03>;
			caps = "MMC_CAP_4_BIT_DATA\0MMC_CAP_MMC_HIGHSPEED\0MMC_CAP_SD_HIGHSPEED\0MMC_CAP_NONREMOVABLE\0MMC_CAP_UHS_SDR12\0MMC_CAP_UHS_SDR25\0MMC_CAP_UHS_SDR50\0MMC_CAP_UHS_SDR104\0MMC_PM_KEEP_POWER\0MMC_CAP_SDIO_IRQ";
			f_min = <0x61a80>;
			f_max = <0xbebc200>;
		};
	};

	nfc@0 {
		compatible = "amlogic, aml_mtd_nand";
		dev_name = "mtdnand";
		status = "disabled";
		reg = <0x00 0xffe07800 0x00 0x200>;
		interrupts = <0x00 0x22 0x01>;
		pinctrl-names = "nand_rb_mod\0nand_norb_mod\0nand_cs_only";
		pinctrl-0 = <0x51>;
		pinctrl-1 = <0x51>;
		pinctrl-2 = <0x52>;
		clocks = <0x0b 0x35 0x0b 0x72>;
		clock-names = "core\0clkin";
		device_id = <0x00>;
		bl_mode = <0x01>;
		fip_copies = <0x04>;
		fip_size = <0x200000>;
		nand_clk_ctrl = <0xffe07000>;
		plat-names = "bootloader\0nandnormal";
		plat-num = <0x02>;
		plat-part-0 = <0x53>;
		plat-part-1 = <0x54>;

		bootloader {
			enable_pad = "ce0";
			busy_pad = "rb0";
			timming_mode = "mode5";
			bch_mode = "bch8_1k";
			t_rea = <0x14>;
			t_rhoh = <0x0f>;
			chip_num = <0x01>;
			part_num = <0x00>;
			rb_detect = <0x01>;
			linux,phandle = <0x53>;
			phandle = <0x53>;
		};

		nandnormal {
			enable_pad = "ce0";
			busy_pad = "rb0";
			timming_mode = "mode5";
			bch_mode = "bch8_1k";
			plane_mode = "twoplane";
			t_rea = <0x14>;
			t_rhoh = <0x0f>;
			chip_num = <0x02>;
			part_num = <0x03>;
			partition = <0x55>;
			rb_detect = <0x01>;
			linux,phandle = <0x54>;
			phandle = <0x54>;
		};

		nand_partition {
			linux,phandle = <0x55>;
			phandle = <0x55>;

			tpl {
				offset = <0x00 0x00>;
				size = <0x00 0x00>;
			};

			logo {
				offset = <0x00 0x00>;
				size = <0x00 0x200000>;
			};

			recovery {
				offset = <0x00 0x00>;
				size = <0x00 0x1000000>;
			};

			boot {
				offset = <0x00 0x00>;
				size = <0x00 0x1000000>;
			};

			system {
				offset = <0x00 0x00>;
				size = <0x00 0x4000000>;
			};

			data {
				offset = <0xffffffff 0xffffffff>;
				size = <0x00 0x00>;
			};
		};
	};

	meson-cooldev@0 {
		status = "okay";
		compatible = "amlogic, meson-cooldev";
		device_name = "mcooldev";

		cooling_devices {

			cpufreq_cool_cluster0 {
				min_state = <0xf4240>;
				dyn_coeff = <0x78>;
				cluster_id = <0x00>;
				gpu_pp = <0x02>;
				node_name = "cpufreq_cool0";
				device_type = "cpufreq";
			};

			cpufreq_cool_cluster1 {
				min_state = <0xf4240>;
				dyn_coeff = <0x1cc>;
				cluster_id = <0x01>;
				gpu_pp = <0x02>;
				node_name = "cpufreq_cool1";
				device_type = "cpufreq";
			};

			cpucore_cool_cluster0 {
				min_state = <0x01>;
				dyn_coeff = <0x00>;
				cluster_id = <0x00>;
				gpu_pp = <0x02>;
				node_name = "cpucore_cool0";
				device_type = "cpucore";
			};

			cpucore_cool_cluster1 {
				min_state = <0x00>;
				dyn_coeff = <0x00>;
				cluster_id = <0x01>;
				gpu_pp = <0x02>;
				node_name = "cpucore_cool1";
				device_type = "cpucore";
			};

			gpufreq_cool {
				min_state = <0x190>;
				dyn_coeff = <0x166>;
				cluster_id = <0x00>;
				gpu_pp = <0x02>;
				node_name = "gpufreq_cool0";
				device_type = "gpufreq";
			};

			gpucore_cool {
				min_state = <0x01>;
				dyn_coeff = <0x00>;
				cluster_id = <0x00>;
				gpu_pp = <0x02>;
				node_name = "gpucore_cool0";
				device_type = "gpucore";
			};
		};

		cpufreq_cool0 {
			#cooling-cells = <0x02>;
			linux,phandle = <0x61>;
			phandle = <0x61>;
		};

		cpufreq_cool1 {
			#cooling-cells = <0x02>;
			linux,phandle = <0x62>;
			phandle = <0x62>;
		};

		cpucore_cool0 {
			#cooling-cells = <0x02>;
			linux,phandle = <0x63>;
			phandle = <0x63>;
		};

		cpucore_cool1 {
			#cooling-cells = <0x02>;
			linux,phandle = <0x64>;
			phandle = <0x64>;
		};

		gpufreq_cool0 {
			#cooling-cells = <0x02>;
			linux,phandle = <0x65>;
			phandle = <0x65>;
		};

		gpucore_cool0 {
			#cooling-cells = <0x02>;
			linux,phandle = <0x66>;
			phandle = <0x66>;
		};
	};

	aml_snd_iomap {
		compatible = "amlogic, snd-iomap";
		status = "okay";
		#address-cells = <0x02>;
		#size-cells = <0x02>;
		ranges;

		pdm_bus {
			reg = <0x00 0xff640000 0x00 0x2000>;
		};

		audiobus_base {
			reg = <0x00 0xff642000 0x00 0x2000>;
		};

		audiolocker_base {
			reg = <0x00 0xff64a000 0x00 0x2000>;
		};

		eqdrc_base {
			reg = <0x00 0xff656000 0x00 0x1800>;
		};

		reset_base {
			reg = <0x00 0xffd01000 0x00 0x1000>;
		};
	};

	pwmao_d-regulator {
		compatible = "pwm-regulator";
		pinctrl-names = "default";
		pinctrl-0 = <0x56>;
		pwms = <0x57 0x01 0x4e2 0x00>;
		regulator-name = "vddcpu0";
		regulator-min-microvolt = <0xb0068>;
		regulator-max-microvolt = <0xf9830>;
		regulator-always-on;
		max-duty-cycle = <0x4e2>;
		voltage-table = <0xf9830 0x00 0xf6d38 0x03 0xf4628 0x06 0xf1f18 0x0a 0xef808 0x0d 0xed0f8 0x10 0xea9e8 0x14 0xe82d8 0x17 0xe5bc8 0x1a 0xe34b8 0x1e 0xe0da8 0x21 0xde698 0x24 0xdbf88 0x28 0xd9878 0x2b 0xd7168 0x2e 0xd4a58 0x32 0xd2348 0x35 0xcfc38 0x38 0xcd528 0x3c 0xcae18 0x3f 0xc8708 0x43 0xc5ff8 0x46 0xc38e8 0x49 0xc11d8 0x4c 0xbeac8 0x50 0xbc3b8 0x53 0xb9ca8 0x56 0xb7598 0x5a 0xb4e88 0x5d 0xb2778 0x60 0xb0068 0x64>;
		status = "okay";
		linux,phandle = <0x1a>;
		phandle = <0x1a>;
	};

	pwmab_a-regulator {
		compatible = "pwm-regulator";
		pinctrl-names = "default";
		pinctrl-0 = <0x58>;
		pwms = <0x59 0x00 0x4e2 0x00>;
		regulator-name = "vddcpu1";
		regulator-min-microvolt = <0xb0068>;
		regulator-max-microvolt = <0xf9830>;
		regulator-always-on;
		max-duty-cycle = <0x4e2>;
		voltage-table = <0xf9830 0x00 0xf6d38 0x03 0xf4628 0x06 0xf1f18 0x0a 0xef808 0x0d 0xed0f8 0x10 0xea9e8 0x14 0xe82d8 0x17 0xe5bc8 0x1a 0xe34b8 0x1e 0xe0da8 0x21 0xde698 0x24 0xdbf88 0x28 0xd9878 0x2b 0xd7168 0x2e 0xd4a58 0x32 0xd2348 0x35 0xcfc38 0x38 0xcd528 0x3c 0xcae18 0x3f 0xc8708 0x43 0xc5ff8 0x46 0xc38e8 0x49 0xc11d8 0x4c 0xbeac8 0x50 0xbc3b8 0x53 0xb9ca8 0x56 0xb7598 0x5a 0xb4e88 0x5d 0xb2778 0x60 0xb0068 0x64>;
		status = "okay";
		linux,phandle = <0x1e>;
		phandle = <0x1e>;
	};

	ddr_bandwidth {
		compatible = "amlogic, ddr-bandwidth";
		status = "okay";
		reg = <0x00 0xff638000 0x00 0x100 0x00 0xff638c00 0x00 0x100>;
		interrupts = <0x00 0x34 0x01>;
		interrupt-names = "ddr_bandwidth";
	};

	dmc_monitor {
		compatible = "amlogic, dmc_monitor";
		status = "okay";
		reg_base = <0xff639000>;
		interrupts = <0x00 0x33 0x01>;
	};

	isp-sc@ff655400 {
		compatible = "amlogic, isp-sc";
		reg = <0x00 0xff655400 0x00 0x1000>;
		reg-names = "isp_sc";
		interrupts = <0x00 0x11 0x00>;
		interrupt-names = "isp_sc";
		linux,phandle = <0x5a>;
		phandle = <0x5a>;
	};

	isp@ff140000 {
		compatible = "arm, isp";
		reg = <0x00 0xff140000 0x00 0x40000>;
		reg-names = "ISP";
		interrupts = <0x00 0x8e 0x04>;
		interrupt-names = "ISP";
		clocks = <0x0b 0xe3 0x0b 0xe4>;
		clock-names = "cts_mipi_isp_clk_composite\0cts_mipi_csi_phy_clk0_composite";
		link-device = <0x5a>;
	};

	isp-adapter@ff650000 {
		compatible = "amlogic, isp-adapter";
		reg = <0x00 0xff650000 0x00 0x6000>;
		reg-names = "adapter";
		interrupts = <0x00 0xb3 0x00>;
		interrupt-names = "adapter-irq";
		linux,phandle = <0x5b>;
		phandle = <0x5b>;
	};

	phy-csi@ff650000 {
		compatible = "amlogic, phy-csi";
		reg = <0x00 0xff650000 0x00 0x2000 0x00 0xff652000 0x00 0x2000 0x00 0xff63c300 0x00 0x100 0x00 0xff654000 0x00 0x100 0x00 0xff654400 0x00 0x100>;
		reg-names = "csi2_phy0\0csi2_phy1\0aphy_reg\0csi0_host\0csi1_host";
		interrupts = <0x00 0x29 0x00 0x00 0x2a 0x00 0x00 0x48 0x00 0x00 0x4a 0x00 0x00 0x57 0x00 0x00 0x58 0x00>;
		interrupt-names = "phy0-irq\0phy1-irq\0csi-host0-intr2\0csi-host0-intr1\0csi-host1-intr2\0csi-host1-intr1";
		link-device = <0x5b>;
	};

	lcd {
		compatible = "amlogic, lcd-g12b";
		dev_name = "lcd";
		mode = "tablet";
		status = "okay";
		key_valid = <0x00>;
		clocks = <0x0b 0x24 0x0b 0x31 0x0b 0x9a 0x0b 0x5d 0x0b 0x5f 0x0b 0x07>;
		clock-names = "dsi_host_gate\0dsi_phy_gate\0dsi_meas\0encl_top_gate\0encl_int_gate\0gp0_pll";
		reg = <0x00 0xffd07000 0x00 0x400 0x00 0xff644000 0x00 0x200>;
		interrupts = <0x00 0x03 0x01>;
		interrupt-names = "vsync";
		pinctrl_version = <0x02>;
		lcd_cpu-gpios = <0x24 0x0a 0x00 0x24 0x09 0x00>;
		lcd_cpu_gpio_names = "GPIOZ_9\0GPIOZ_8";

		lcd_0 {
			model_name = "B080XAN01";
			interface = "mipi";
			basic_setting = <0x300 0x400 0x3b4 0x474 0x08 0x77 0x9f>;
			lcd_timing = <0x40 0x38 0x00 0x32 0x1e 0x00>;
			clk_attr = <0x00 0x00 0x01 0x3dd6dc0>;
			mipi_attr = <0x04 0x226 0x00 0x01 0x00 0x02 0x01 0x00>;
			dsi_init_on = <0x05 0x01 0x11 0xff 0x14 0x05 0x01 0x29 0xff 0x14 0xff 0xff>;
			dsi_init_off = <0x05 0x01 0x28 0xff 0x0a 0x05 0x01 0x10 0xff 0x0a 0xff 0xff>;
			extern_init = <0xff>;
			power_on_step = <0x00 0x01 0x00 0x64 0x00 0x00 0x00 0x0a 0x00 0x00 0x01 0x14 0x02 0x00 0x00 0x00 0xff 0x00 0x00 0x00>;
			power_off_step = <0x02 0x00 0x00 0x32 0x00 0x00 0x00 0x0a 0x00 0x01 0x01 0x64 0xff 0x00 0x00 0x00>;
			backlight_index = <0x00>;
		};

		lcd_1 {
			model_name = "TL070WSH27";
			interface = "mipi";
			basic_setting = <0x400 0x258 0x4e2 0x276 0x08 0x9a 0x56>;
			lcd_timing = <0x50 0x64 0x00 0x05 0x14 0x00>;
			clk_attr = <0x00 0x00 0x01 0x2d0fa50>;
			mipi_attr = <0x04 0x12c 0x00 0x01 0x00 0x02 0x01 0x00>;
			dsi_init_on = <0x05 0x01 0x11 0xff 0xc8 0x05 0x01 0x29 0xff 0x14 0xff 0xff>;
			dsi_init_off = <0x05 0x01 0x28 0xff 0x0a 0x05 0x01 0x10 0xff 0x0a 0xff 0xff>;
			extern_init = <0xff>;
			power_on_step = <0x00 0x01 0x00 0x64 0x00 0x00 0x00 0x0a 0x00 0x00 0x01 0x14 0x02 0x00 0x00 0x00 0xff 0x00 0x00 0x00>;
			power_off_step = <0x02 0x00 0x00 0x32 0x00 0x00 0x00 0x0a 0x00 0x01 0x01 0x64 0xff 0x00 0x00 0x00>;
			backlight_index = <0x00>;
		};

		lcd_2 {
			model_name = "TL070HDV03CT";
			interface = "mipi";
			basic_setting = <0x2d0 0x500 0x3ca 0x554 0x08 0x57 0x9a>;
			lcd_timing = <0x0a 0x78 0x00 0x04 0x28 0x00>;
			clk_attr = <0x00 0x00 0x01 0x4bb51a8>;
			mipi_attr = <0x04 0x1f4 0x00 0x01 0x00 0x02 0x01 0x00>;
			dsi_init_on = <0xff 0xff>;
			dsi_init_off = <0xff 0xff>;
			extern_init = <0x01>;
			power_on_step = <0x00 0x01 0x00 0x64 0x00 0x00 0x00 0x0a 0x00 0x00 0x01 0x14 0x02 0x00 0x00 0x00 0xff 0x00 0x00 0x00>;
			power_off_step = <0x02 0x00 0x00 0x32 0x00 0x00 0x00 0x0a 0x00 0x01 0x01 0x64 0xff 0x00 0x00 0x00>;
			backlight_index = <0x00>;
		};

		lcd_3 {
			model_name = "P070ACB_FT";
			interface = "mipi";
			basic_setting = <0x258 0x400 0x302 0x42e 0x08 0x03 0x05>;
			lcd_timing = <0x0a 0x50 0x00 0x06 0x14 0x00>;
			clk_attr = <0x00 0x00 0x01 0x2f24d90>;
			mipi_attr = <0x04 0x190 0x00 0x01 0x00 0x02 0x00 0x00>;
			dsi_init_on = <0xff 0x0a 0xf0 0x03 0x00 0x01 0x1e 0xf0 0x03 0x00 0x00 0x0a 0xf0 0x03 0x00 0x01 0x1e 0xfc 0x02 0x04 0x03 0xff 0xff>;
			dsi_init_off = <0xff 0xff>;
			extern_init = <0x02>;
			power_on_step = <0x00 0x01 0x00 0xc8 0x02 0x00 0x00 0x00 0xff 0x00 0x00 0x00>;
			power_off_step = <0x02 0x00 0x00 0x00 0x00 0x00 0x00 0x14 0x00 0x01 0x01 0x64 0xff 0x00 0x00 0x00>;
			backlight_index = <0x00>;
		};
	};

	lcd_extern {
		compatible = "amlogic, lcd_extern";
		dev_name = "lcd_extern";
		status = "okay";
		i2c_bus = "i2c_bus_0";
		key_valid = <0x00>;

		extern_0 {
			index = <0x00>;
			extern_name = "mipi_default";
			status = "okay";
			type = <0x02>;
			cmd_size = <0xff>;
			init_on = <0xff 0x0a 0x05 0x01 0x11 0xff 0x78 0x05 0x01 0x29 0xff 0xff>;
			init_off = <0x05 0x01 0x28 0xff 0x0a 0x05 0x01 0x10 0xff 0x96 0xff 0xff>;
		};

		extern_1 {
			index = <0x01>;
			extern_name = "mipi_default";
			status = "okay";
			type = <0x02>;
			cmd_size = <0xff>;
			init_on = <0x39 0x04 0xff 0x98 0x81 0x03 0x15 0x02 0x01 0x00 0x15 0x02 0x02 0x00 0x15 0x02 0x03 0x72 0x15 0x02 0x04 0x00 0x15 0x02 0x05 0x00 0x15 0x02 0x06 0x09 0x15 0x02 0x07 0x00 0x15 0x02 0x08 0x00 0x15 0x02 0x09 0x01 0x15 0x02 0x0a 0x00 0x15 0x02 0x0b 0x00 0x15 0x02 0x0c 0x01 0x15 0x02 0x0d 0x00 0x15 0x02 0x0e 0x00 0x15 0x02 0x0f 0x14 0x15 0x02 0x10 0x14 0x15 0x02 0x11 0x00 0x15 0x02 0x12 0x00 0x15 0x02 0x13 0x00 0x15 0x02 0x14 0x00 0x15 0x02 0x15 0x00 0x15 0x02 0x16 0x00 0x15 0x02 0x17 0x00 0x15 0x02 0x18 0x00 0x15 0x02 0x19 0x00 0x15 0x02 0x1a 0x00 0x15 0x02 0x1b 0x00 0x15 0x02 0x1c 0x00 0x15 0x02 0x1d 0x00 0x15 0x02 0x1e 0x40 0x15 0x02 0x1f 0x80 0x15 0x02 0x20 0x05 0x15 0x02 0x21 0x02 0x15 0x02 0x22 0x00 0x15 0x02 0x23 0x00 0x15 0x02 0x24 0x00 0x15 0x02 0x25 0x00 0x15 0x02 0x26 0x00 0x15 0x02 0x27 0x00 0x15 0x02 0x28 0x33 0x15 0x02 0x29 0x02 0x15 0x02 0x2a 0x00 0x15 0x02 0x2b 0x00 0x15 0x02 0x2c 0x00 0x15 0x02 0x2d 0x00 0x15 0x02 0x2e 0x00 0x15 0x02 0x2f 0x00 0x15 0x02 0x30 0x00 0x15 0x02 0x31 0x00 0x15 0x02 0x32 0x00 0x15 0x02 0x33 0x00 0x15 0x02 0x34 0x04 0x15 0x02 0x35 0x00 0x15 0x02 0x36 0x00 0x15 0x02 0x37 0x00 0x15 0x02 0x38 0x3c 0x15 0x02 0x39 0x00 0x15 0x02 0x3a 0x00 0x15 0x02 0x3b 0x00 0x15 0x02 0x3c 0x00 0x15 0x02 0x3d 0x00 0x15 0x02 0x3e 0x00 0x15 0x02 0x3f 0x00 0x15 0x02 0x40 0x00 0x15 0x02 0x41 0x00 0x15 0x02 0x42 0x00 0x15 0x02 0x43 0x00 0x15 0x02 0x44 0x00 0x15 0x02 0x50 0x10 0x15 0x02 0x51 0x32 0x15 0x02 0x52 0x54 0x15 0x02 0x53 0x76 0x15 0x02 0x54 0x98 0x15 0x02 0x55 0xba 0x15 0x02 0x56 0x10 0x15 0x02 0x57 0x32 0x15 0x02 0x58 0x54 0x15 0x02 0x59 0x76 0x15 0x02 0x5a 0x98 0x15 0x02 0x5b 0xba 0x15 0x02 0x5c 0xdc 0x15 0x02 0x5d 0xfe 0x15 0x02 0x5e 0x00 0x15 0x02 0x5f 0x0e 0x15 0x02 0x60 0x0f 0x15 0x02 0x61 0x0c 0x15 0x02 0x62 0x0d 0x15 0x02 0x63 0x06 0x15 0x02 0x64 0x07 0x15 0x02 0x65 0x02 0x15 0x02 0x66 0x02 0x15 0x02 0x67 0x02 0x15 0x02 0x68 0x02 0x15 0x02 0x69 0x01 0x15 0x02 0x6a 0x00 0x15 0x02 0x6b 0x02 0x15 0x02 0x6c 0x15 0x15 0x02 0x6d 0x14 0x15 0x02 0x6e 0x02 0x15 0x02 0x6f 0x02 0x15 0x02 0x70 0x02 0x15 0x02 0x71 0x02 0x15 0x02 0x72 0x02 0x15 0x02 0x73 0x02 0x15 0x02 0x74 0x02 0x15 0x02 0x75 0x0e 0x15 0x02 0x76 0x0f 0x15 0x02 0x77 0x0c 0x15 0x02 0x78 0x0d 0x15 0x02 0x79 0x06 0x15 0x02 0x7a 0x07 0x15 0x02 0x7b 0x02 0x15 0x02 0x7c 0x02 0x15 0x02 0x7d 0x02 0x15 0x02 0x7e 0x02 0x15 0x02 0x7f 0x01 0x15 0x02 0x80 0x00 0x15 0x02 0x81 0x02 0x15 0x02 0x82 0x14 0x15 0x02 0x83 0x15 0x15 0x02 0x84 0x02 0x15 0x02 0x85 0x02 0x15 0x02 0x86 0x02 0x15 0x02 0x87 0x02 0x15 0x02 0x88 0x02 0x15 0x02 0x89 0x02 0x15 0x02 0x8a 0x02 0x39 0x04 0xff 0x98 0x81 0x04 0x15 0x02 0x6c 0x15 0x15 0x02 0x6e 0x2a 0x15 0x02 0x6f 0x33 0x15 0x02 0x3a 0x94 0x15 0x02 0x8d 0x14 0x15 0x02 0x87 0xba 0x15 0x02 0x26 0x76 0x15 0x02 0xb2 0xd1 0x15 0x02 0xb5 0x06 0x39 0x04 0xff 0x98 0x81 0x01 0x15 0x02 0x22 0x02 0x15 0x02 0x31 0x00 0x15 0x02 0x53 0x72 0x15 0x02 0x55 0x88 0x15 0x02 0x40 0x33 0x15 0x02 0x50 0x96 0x15 0x02 0x51 0x96 0x15 0x02 0x60 0x08 0x15 0x02 0xa0 0x08 0x15 0x02 0xa1 0x1d 0x15 0x02 0xa2 0x2a 0x15 0x02 0xa3 0x10 0x15 0x02 0xa4 0x15 0x15 0x02 0xa5 0x28 0x15 0x02 0xa6 0x1c 0x15 0x02 0xa7 0x1d 0x15 0x02 0xa8 0x7e 0x15 0x02 0xa9 0x1d 0x15 0x02 0xaa 0x29 0x15 0x02 0xab 0x6b 0x15 0x02 0xac 0x1a 0x15 0x02 0xad 0x18 0x15 0x02 0xae 0x4b 0x15 0x02 0xaf 0x20 0x15 0x02 0xb0 0x27 0x15 0x02 0xb1 0x50 0x15 0x02 0xb2 0x64 0x15 0x02 0xb3 0x39 0x15 0x02 0xc0 0x08 0x15 0x02 0xc1 0x1d 0x15 0x02 0xc2 0x2a 0x15 0x02 0xc3 0x10 0x15 0x02 0xc4 0x15 0x15 0x02 0xc5 0x28 0x15 0x02 0xc6 0x1c 0x15 0x02 0xc7 0x1d 0x15 0x02 0xc8 0x7e 0x15 0x02 0xc9 0x1d 0x15 0x02 0xca 0x29 0x15 0x02 0xcb 0x6b 0x15 0x02 0xcc 0x1a 0x15 0x02 0xcd 0x18 0x15 0x02 0xce 0x4b 0x15 0x02 0xcf 0x20 0x15 0x02 0xd0 0x27 0x15 0x02 0xd1 0x50 0x15 0x02 0xd2 0x64 0x15 0x02 0xd3 0x39 0x39 0x04 0xff 0x98 0x81 0x00 0x15 0x02 0x3a 0x77 0xff 0x02 0x15 0x02 0x36 0x08 0x05 0x01 0x11 0xff 0xc8 0x05 0x01 0x29 0xff 0xc8 0xff 0xff>;
			init_off = <0x05 0x01 0x28 0xff 0x0a 0x05 0x01 0x10 0xff 0x96 0xff 0xff>;
		};

		extern_2 {
			index = <0x02>;
			extern_name = "mipi_default";
			status = "okay";
			type = <0x02>;
			cmd_size = <0xff>;
			init_on = <0x23 0x02 0xe0 0x00 0x23 0x02 0xe1 0x93 0x23 0x02 0xe2 0x65 0x23 0x02 0xe3 0xf8 0x23 0x02 0x80 0x03 0x23 0x02 0xe0 0x01 0x23 0x02 0x0c 0x74 0x23 0x02 0x17 0x00 0x23 0x02 0x18 0xef 0x23 0x02 0x19 0x00 0x23 0x02 0x1a 0x00 0x23 0x02 0x1b 0xef 0x23 0x02 0x1c 0x00 0x23 0x02 0x1f 0x70 0x23 0x02 0x20 0x2d 0x23 0x02 0x21 0x2d 0x23 0x02 0x22 0x7e 0x23 0x02 0x26 0xf3 0x23 0x02 0x37 0x09 0x23 0x02 0x38 0x04 0x23 0x02 0x39 0x00 0x23 0x02 0x3a 0x01 0x23 0x02 0x3c 0x90 0x23 0x02 0x3d 0xff 0x23 0x02 0x3e 0xff 0x23 0x02 0x3f 0xff 0x23 0x02 0x40 0x02 0x23 0x02 0x41 0x80 0x23 0x02 0x42 0x99 0x23 0x02 0x43 0x14 0x23 0x02 0x44 0x19 0x23 0x02 0x45 0x5a 0x23 0x02 0x4b 0x04 0x23 0x02 0x55 0x02 0x23 0x02 0x56 0x01 0x23 0x02 0x57 0x69 0x23 0x02 0x58 0x0a 0x23 0x02 0x59 0x0a 0x23 0x02 0x5a 0x2e 0x23 0x02 0x5b 0x19 0x23 0x02 0x5c 0x15 0x23 0x02 0x5d 0x77 0x23 0x02 0x5e 0x56 0x23 0x02 0x5f 0x45 0x23 0x02 0x60 0x38 0x23 0x02 0x61 0x35 0x23 0x02 0x62 0x27 0x23 0x02 0x63 0x2d 0x23 0x02 0x64 0x18 0x23 0x02 0x65 0x33 0x23 0x02 0x66 0x34 0x23 0x02 0x67 0x35 0x23 0x02 0x68 0x56 0x23 0x02 0x69 0x45 0x23 0x02 0x6a 0x4f 0x23 0x02 0x6b 0x42 0x23 0x02 0x6c 0x40 0x23 0x02 0x6d 0x34 0x23 0x02 0x6e 0x25 0x23 0x02 0x6f 0x02 0x23 0x02 0x70 0x77 0x23 0x02 0x71 0x56 0x23 0x02 0x72 0x45 0x23 0x02 0x73 0x38 0x23 0x02 0x74 0x35 0x23 0x02 0x75 0x27 0x23 0x02 0x76 0x2d 0x23 0x02 0x77 0x18 0x23 0x02 0x78 0x33 0x23 0x02 0x79 0x34 0x23 0x02 0x7a 0x35 0x23 0x02 0x7b 0x56 0x23 0x02 0x7c 0x45 0x23 0x02 0x7d 0x4f 0x23 0x02 0x7e 0x42 0x23 0x02 0x7f 0x40 0x23 0x02 0x80 0x34 0x23 0x02 0x81 0x25 0x23 0x02 0x82 0x02 0x23 0x02 0xe0 0x02 0x23 0x02 0x00 0x53 0x23 0x02 0x01 0x55 0x23 0x02 0x02 0x55 0x23 0x02 0x03 0x51 0x23 0x02 0x04 0x77 0x23 0x02 0x05 0x57 0x23 0x02 0x06 0x1f 0x23 0x02 0x07 0x4f 0x23 0x02 0x08 0x4d 0x23 0x02 0x09 0x1f 0x23 0x02 0x0a 0x4b 0x23 0x02 0x0b 0x49 0x23 0x02 0x0c 0x1f 0x23 0x02 0x0d 0x47 0x23 0x02 0x0e 0x45 0x23 0x02 0x0f 0x41 0x23 0x02 0x10 0x1f 0x23 0x02 0x11 0x1f 0x23 0x02 0x12 0x1f 0x23 0x02 0x13 0x55 0x23 0x02 0x14 0x1f 0x23 0x02 0x15 0x1f 0x23 0x02 0x16 0x52 0x23 0x02 0x17 0x55 0x23 0x02 0x18 0x55 0x23 0x02 0x19 0x50 0x23 0x02 0x1a 0x77 0x23 0x02 0x1b 0x57 0x23 0x02 0x1c 0x1f 0x23 0x02 0x1d 0x4e 0x23 0x02 0x1e 0x4c 0x23 0x02 0x1f 0x1f 0x23 0x02 0x20 0x4a 0x23 0x02 0x21 0x48 0x23 0x02 0x22 0x1f 0x23 0x02 0x23 0x46 0x23 0x02 0x24 0x44 0x23 0x02 0x25 0x40 0x23 0x02 0x26 0x1f 0x23 0x02 0x27 0x1f 0x23 0x02 0x28 0x1f 0x23 0x02 0x29 0x1f 0x23 0x02 0x2a 0x1f 0x23 0x02 0x2b 0x55 0x23 0x02 0x2c 0x12 0x23 0x02 0x2d 0x15 0x23 0x02 0x2e 0x15 0x23 0x02 0x2f 0x00 0x23 0x02 0x30 0x37 0x23 0x02 0x31 0x17 0x23 0x02 0x32 0x1f 0x23 0x02 0x33 0x08 0x23 0x02 0x34 0x0a 0x23 0x02 0x35 0x1f 0x23 0x02 0x36 0x0c 0x23 0x02 0x37 0x0e 0x23 0x02 0x38 0x1f 0x23 0x02 0x39 0x04 0x23 0x02 0x3a 0x06 0x23 0x02 0x3b 0x10 0x23 0x02 0x3c 0x1f 0x23 0x02 0x3d 0x1f 0x23 0x02 0x3e 0x1f 0x23 0x02 0x3f 0x15 0x23 0x02 0x40 0x1f 0x23 0x02 0x41 0x1f 0x23 0x02 0x42 0x13 0x23 0x02 0x43 0x15 0x23 0x02 0x44 0x15 0x23 0x02 0x45 0x01 0x23 0x02 0x46 0x37 0x23 0x02 0x47 0x17 0x23 0x02 0x48 0x1f 0x23 0x02 0x49 0x09 0x23 0x02 0x4a 0x0b 0x23 0x02 0x4b 0x1f 0x23 0x02 0x4c 0x0d 0x23 0x02 0x4d 0x0f 0x23 0x02 0x4e 0x1f 0x23 0x02 0x4f 0x05 0x23 0x02 0x50 0x07 0x23 0x02 0x51 0x11 0x23 0x02 0x52 0x1f 0x23 0x02 0x53 0x1f 0x23 0x02 0x54 0x1f 0x23 0x02 0x55 0x1f 0x23 0x02 0x56 0x1f 0x23 0x02 0x57 0x15 0x23 0x02 0x58 0x40 0x23 0x02 0x59 0x00 0x23 0x02 0x5a 0x00 0x23 0x02 0x5b 0x10 0x23 0x02 0x5c 0x14 0x23 0x02 0x5d 0x40 0x23 0x02 0x5e 0x01 0x23 0x02 0x5f 0x02 0x23 0x02 0x60 0x40 0x23 0x02 0x61 0x03 0x23 0x02 0x62 0x04 0x23 0x02 0x63 0x7a 0x23 0x02 0x64 0x7a 0x23 0x02 0x65 0x74 0x23 0x02 0x66 0x16 0x23 0x02 0x67 0xb4 0x23 0x02 0x68 0x16 0x23 0x02 0x69 0x7a 0x23 0x02 0x6a 0x7a 0x23 0x02 0x6b 0x0c 0x23 0x02 0x6c 0x00 0x23 0x02 0x6d 0x04 0x23 0x02 0x6e 0x04 0x23 0x02 0x6f 0x88 0x23 0x02 0x70 0x00 0x23 0x02 0x71 0x00 0x23 0x02 0x72 0x06 0x23 0x02 0x73 0x7b 0x23 0x02 0x74 0x00 0x23 0x02 0x75 0xbc 0x23 0x02 0x76 0x00 0x23 0x02 0x77 0x04 0x23 0x02 0x78 0x2c 0x23 0x02 0x79 0x00 0x23 0x02 0x7a 0x00 0x23 0x02 0x7b 0x00 0x23 0x02 0x7c 0x00 0x23 0x02 0x7d 0x03 0x23 0x02 0x7e 0x7b 0x23 0x02 0xe0 0x04 0x23 0x02 0x09 0x11 0x23 0x02 0x0e 0x48 0x23 0x02 0x2b 0x2b 0x23 0x02 0x2e 0x44 0x23 0x02 0xe0 0x00 0x23 0x02 0xe6 0x02 0x23 0x02 0xe7 0x0c 0x05 0x01 0x11 0xff 0x78 0x05 0x01 0x29 0x05 0x01 0x35 0xff 0x14 0xff 0xff>;
			init_off = <0x05 0x01 0x28 0xff 0x0a 0x05 0x01 0x10 0xff 0x96 0xff 0xff>;
		};
	};

	backlight {
		compatible = "amlogic, backlight-g12b";
		dev_name = "backlight";
		status = "okay";
		key_valid = <0x00>;
		pinctrl-names = "pwm_on";
		pinctrl-0 = <0x5c>;
		pinctrl_version = <0x02>;
		bl_pwm_config = <0x5d>;
		bl-gpios = <0x24 0x15 0x00 0x24 0x16 0x00>;
		bl_gpio_names = "GPIOH_4\0GPIOH_5";

		backlight_0 {
			index = <0x00>;
			bl_name = "backlight_pwm";
			bl_level_default_uboot_kernel = <0x64 0x64>;
			bl_level_attr = <0xff 0x0a 0x80 0x80>;
			bl_ctrl_method = <0x01>;
			bl_power_attr = <0x00 0x01 0x00 0xc8 0xc8>;
			bl_pwm_port = "PWM_F";
			bl_pwm_attr = <0x00 0xb4 0x64 0x19>;
			bl_pwm_power = <0x01 0x01 0x0a 0x0a>;
			bl_pwm_en_sequence_reverse = <0x00>;
		};

		backlight_1 {
			index = <0x01>;
			bl_name = "bl_extern";
			bl_level_default_uboot_kernel = <0x64 0x64>;
			bl_level_attr = <0xff 0x0a 0x80 0x80>;
			bl_ctrl_method = <0x04>;
			bl_power_attr = <0x01 0x01 0x00 0xc8 0xc8>;
			bl_extern_index = <0x00>;
		};
	};

	bl_pwm_conf {
		linux,phandle = <0x5d>;
		phandle = <0x5d>;

		pwm_channel_0 {
			pwm_port_index = <0x05>;
			pwms = <0x5e 0x01 0x7558 0x00>;
		};
	};

	bl_extern {
		compatible = "amlogic, bl_extern";
		dev_name = "bl_extern";
		status = "disabled";

		extern_0 {
			index = <0x00>;
			extern_name = "i2c_lp8556";
			type = <0x00>;
			i2c_address = <0x2c>;
			i2c_bus = "i2c_bus_c";
			dim_max_min = <0xff 0x0a>;
		};

		extern_1 {
			index = <0x01>;
			extern_name = "mipi_lt070me05";
			type = <0x02>;
			dim_max_min = <0xff 0x0a>;
		};
	};

	thermal-zones {

		soc_thermal {
			polling-delay = <0x3e8>;
			polling-delay-passive = <0x64>;
			sustainable-power = <0xdde>;
			thermal-sensors = <0x5f 0x00>;

			trips {

				trip-point@0 {
					temperature = <0xea60>;
					hysteresis = <0x1388>;
					type = "passive";
				};

				trip-point@1 {
					temperature = <0x124f8>;
					hysteresis = <0x1388>;
					type = "passive";
					linux,phandle = <0x60>;
					phandle = <0x60>;
				};

				trip-point@2 {
					temperature = <0x14c08>;
					hysteresis = <0x1388>;
					type = "hot";
				};

				trip-point@3 {
					temperature = <0x249f0>;
					hysteresis = <0x3e8>;
					type = "critical";
				};
			};

			cooling-maps {

				cpufreq_cooling_map0 {
					trip = <0x60>;
					cooling-device = <0x61 0x00 0x09>;
					contribution = <0x400>;
				};

				cpufreq_cooling_map1 {
					trip = <0x60>;
					cooling-device = <0x62 0x00 0x09>;
					contribution = <0x400>;
				};

				cpucore_cooling_map0 {
					trip = <0x60>;
					cooling-device = <0x63 0x00 0x01>;
					contribution = <0x400>;
				};

				cpucore_cooling_map1 {
					trip = <0x60>;
					cooling-device = <0x64 0x00 0x04>;
					contribution = <0x400>;
				};

				gpufreq_cooling_map {
					trip = <0x60>;
					cooling-device = <0x65 0x00 0x04>;
					contribution = <0x400>;
				};

				gpucore_cooling_map {
					trip = <0x60>;
					cooling-device = <0x66 0x00 0x02>;
					contribution = <0x400>;
				};
			};
		};

		ddr_thermal {
			polling-delay = <0x3e8>;
			polling-delay-passive = <0x64>;
			sustainable-power = <0xdde>;
			thermal-sensors = <0x67 0x01>;

			trips {

				trip-point@0 {
					temperature = <0xea60>;
					hysteresis = <0x1388>;
					type = "passive";
				};

				trip-point@1 {
					temperature = <0x124f8>;
					hysteresis = <0x1388>;
					type = "passive";
				};

				trip-point@2 {
					temperature = <0x14c08>;
					hysteresis = <0x1388>;
					type = "hot";
				};

				trip-point@3 {
					temperature = <0x249f0>;
					hysteresis = <0x3e8>;
					type = "critical";
				};
			};
		};

		board_thermal {
			polling-delay = <0x3e8>;
			polling-delay-passive = <0x64>;
			sustainable-power = <0x866>;
			policy = "step_wise";
			thermal-sensors = <0x68>;

			trips {

				trip-point@0 {
					temperature = <0xee48>;
					hysteresis = <0x3e8>;
					type = "passive";
					linux,phandle = <0x69>;
					phandle = <0x69>;
				};

				trip-point@1 {
					temperature = <0x13880>;
					hysteresis = <0x3e8>;
					type = "passive";
					linux,phandle = <0x6a>;
					phandle = <0x6a>;
				};

				trip-point@2 {
					temperature = <0x14c08>;
					hysteresis = <0x3e8>;
					type = "passive";
					linux,phandle = <0x6b>;
					phandle = <0x6b>;
				};

				trip-point@3 {
					temperature = <0x17318>;
					hysteresis = <0x3e8>;
					type = "passive";
					linux,phandle = <0x6c>;
					phandle = <0x6c>;
				};

				trip-point@4 {
					temperature = <0x3f7a0>;
					hysteresis = <0x3e8>;
					type = "critical";
				};
			};

			cooling-maps {

				cpufreq_cooling_map0 {
					trip = <0x69>;
					cooling-device = <0x61 0x01 0x02>;
				};

				cpufreq_cooling_map1 {
					trip = <0x6a>;
					cooling-device = <0x61 0x02 0x03>;
					contribution = <0x400>;
				};

				cpufreq_cooling_map2 {
					trip = <0x6b>;
					cooling-device = <0x61 0x03 0x04>;
					contribution = <0x400>;
				};

				cpufreq_cooling_map3 {
					trip = <0x6c>;
					cooling-device = <0x61 0x04 0x05>;
					contribution = <0x400>;
				};

				gpufreq_cooling_map1 {
					trip = <0x6a>;
					cooling-device = <0x65 0x01 0x02>;
					contribution = <0x400>;
				};

				gpufreq_cooling_map2 {
					trip = <0x6b>;
					cooling-device = <0x65 0x02 0x03>;
					contribution = <0x400>;
				};

				gpufreq_cooling_map3 {
					trip = <0x6c>;
					cooling-device = <0x65 0x03 0x04>;
					contribution = <0x400>;
				};

				cpucore_cooling_map1 {
					trip = <0x6a>;
					cooling-device = <0x64 0x00 0x01>;
					contribution = <0x400>;
				};

				cpucore_cooling_map2 {
					trip = <0x6b>;
					cooling-device = <0x64 0x01 0x02>;
					contribution = <0x400>;
				};

				gpucore_cooling_map2 {
					trip = <0x6b>;
					cooling-device = <0x66 0x00 0x01>;
					contribution = <0x400>;
				};

				gpucore_cooling_map3 {
					trip = <0x6c>;
					cooling-device = <0x66 0x01 0x02>;
					contribution = <0x400>;
				};

				wifi_cooling_map {
					trip = <0x6a>;
					cooling-device = <0x6d 0x00 0x01>;
					contribution = <0x400>;
				};
			};
		};
	};

	aliases {
		serial0 = "/soc/aobus@ff800000/serial@3000";
		serial1 = "/serial@ffd24000";
		serial2 = "/serial@ffd23000";
		serial3 = "/serial@ffd22000";
		serial4 = "/soc/aobus@ff800000/serial@4000";
		i2c0 = "/soc/cbus@ffd00000/i2c@1f000";
		i2c1 = "/soc/cbus@ffd00000/i2c@1e000";
		i2c2 = "/soc/cbus@ffd00000/i2c@1d000";
		i2c3 = "/soc/cbus@ffd00000/i2c@1c000";
		i2c4 = "/soc/aobus@ff800000/i2c@5000";
		tsensor0 = "/p_tsensor@ff634594";
		tsensor1 = "/d_tsensor@ff800228";
	};

	memory@00000000 {
		device_type = "memory";
		linux,usable-memory = <0x00 0x100000 0x00 0x7ff00000>;
	};

	reserved-memory {
		#address-cells = <0x02>;
		#size-cells = <0x02>;
		ranges;

		ramoops@0x07400000 {
			compatible = "ramoops";
			reg = <0x00 0x7400000 0x00 0x100000>;
			record-size = <0x8000>;
			console-size = <0x8000>;
			ftrace-size = <0x00>;
			pmsg-size = <0x8000>;
		};

		linux,secmon {
			compatible = "shared-dma-pool";
			reusable;
			size = <0x00 0x2400000>;
			alignment = <0x00 0x400000>;
			alloc-ranges = <0x00 0x5000000 0x00 0x2400000>;
			linux,phandle = <0x1f>;
			phandle = <0x1f>;
		};

		linux,secos {
			status = "disable";
			compatible = "amlogic, aml_secos_memory";
			reg = <0x00 0x5300000 0x00 0x2000000>;
			no-map;
		};

		linux,meson-fb {
			compatible = "shared-dma-pool";
			reusable;
			size = <0x00 0x800000>;
			alignment = <0x00 0x400000>;
			alloc-ranges = <0x00 0x7f800000 0x00 0x800000>;
			linux,phandle = <0x44>;
			phandle = <0x44>;
		};

		linux,ion-dev {
			compatible = "shared-dma-pool";
			reusable;
			size = <0x00 0x8000000>;
			alignment = <0x00 0x400000>;
			linux,phandle = <0x2a>;
			phandle = <0x2a>;
		};

		linux,di_cma {
			compatible = "shared-dma-pool";
			reusable;
			size = <0x00 0x2800000>;
			alignment = <0x00 0x400000>;
			linux,phandle = <0x72>;
			phandle = <0x72>;
		};

		linux,codec_mm_cma {
			compatible = "shared-dma-pool";
			reusable;
			size = <0x00 0x13400000>;
			alignment = <0x00 0x400000>;
			linux,contiguous-region;
			linux,phandle = <0x70>;
			phandle = <0x70>;
		};

		linux,codec_mm_reserved {
			compatible = "amlogic, codec-mm-reserved";
			size = <0x00 0x00>;
			alignment = <0x00 0x100000>;
			linux,phandle = <0x71>;
			phandle = <0x71>;
		};

		linux,vdin0_cma {
			compatible = "shared-dma-pool";
			reusable;
			size = <0x00 0x4000000>;
			alignment = <0x00 0x400000>;
			linux,phandle = <0x42>;
			phandle = <0x42>;
		};

		linux,vdin1_cma {
			compatible = "shared-dma-pool";
			reusable;
			size = <0x00 0x4000000>;
			alignment = <0x00 0x400000>;
			linux,phandle = <0x43>;
			phandle = <0x43>;
		};
	};

	cvbsout {
		compatible = "amlogic, cvbsout-g12b";
		dev_name = "cvbsout";
		status = "okay";
		clocks = <0x0b 0x55 0x0b 0x4e 0x0b 0x4f 0x0b 0x57>;
		clock-names = "venci_top_gate\0venci_0_gate\0venci_1_gate\0vdac_clk_gate";
		clk_path = <0x00>;
		performance = <0x1bf0 0x09 0x1b56 0x333 0x1b12 0x8080 0x1b05 0xfd 0x1c59 0xf850 0xffff 0x00>;
		performance_sarft = <0x1bf0 0x09 0x1b56 0x333 0x1b12 0x00 0x1b05 0x09 0x1c59 0xfc48 0xffff 0x00>;
	};

	bt-dev {
		compatible = "amlogic, bt-dev";
		dev_name = "bt-dev";
		status = "okay";
		gpio_en = <0x24 0x50 0x00>;
	};

	wifi {
		compatible = "amlogic, aml_wifi";
		dev_name = "aml_wifi";
		status = "okay";
		interrupt_pin = <0x24 0x49 0x00>;
		irq_trigger_type = "GPIO_IRQ_LOW";
		power_on_pin = <0x24 0x51 0x00>;
		power_pin_reset = <0x01>;
		dhd_static_buf;
		pinctrl-names = "default";
		pinctrl-0 = <0x6e>;
		pwm_config = <0x6f>;
	};

	wifi_pwm_conf {
		linux,phandle = <0x6f>;
		phandle = <0x6f>;

		pwm_channel1_conf {
			pwms = <0x5e 0x00 0x7558 0x00>;
			duty-cycle = <0x3aac>;
			times = <0x0a>;
		};

		pwm_channel2_conf {
			pwms = <0x5e 0x02 0x754e 0x00>;
			duty-cycle = <0x3aa7>;
			times = <0x0c>;
		};
	};

	codec_mm {
		compatible = "amlogic, codec, mm";
		memory-region = <0x70 0x71>;
		dev_name = "codec_mm";
		status = "okay";
	};

	deinterlace {
		compatible = "amlogic, deinterlace";
		status = "okay";
		flag_cma = <0x01>;
		memory-region = <0x72>;
		interrupts = <0x00 0x2e 0x01 0x00 0x28 0x01>;
		interrupt-names = "pre_irq\0post_irq";
		clocks = <0x0b 0x9b 0x0b 0x9c>;
		clock-names = "vpu_clkb_tmp_composite\0vpu_clkb_composite";
		clock-range = <0x14e 0x29b>;
		buffer-size = <0x3e2c40>;
		post-wr-support = <0x01>;
		nr10bit-support = <0x01>;
		nrds-enable = <0x01>;
		pps-enable = <0x01>;
	};

	ionvideo {
		compatible = "amlogic, ionvideo";
		dev_name = "ionvideo";
		status = "okay";
	};

	gpio_keypad {
		compatible = "amlogic, gpio_keypad";
		status = "okay";
		scan_period = <0x14>;
		key_num = <0x04>;
		key_name = "mute\0action\0volup\0voldown";
		key_code = <0x71 0x8a 0x72 0x73>;
		key_pin = <0x24 0x52 0x00 0x24 0x48 0x00 0x24 0x4f 0x00 0x24 0x4e 0x00>;
		interrupts = <0x00 0x46 0x01 0x00 0x47 0x02>;
		interrupt-names = "irq_keyup\0irq_keydown";
	};

	amz_privacy {
		gpios = <0x24 0x3b 0x00>;
	};

	adc_keypad {
		compatible = "amlogic, adc_keypad";
		status = "okay";
		key_name = "up\0down\0left\0right";
		key_num = <0x04>;
		io-channels = <0x73 0x02>;
		io-channel-names = "key-chan-2";
		key_chan = <0x02 0x02 0x02 0x02>;
		key_code = <0x67 0x6c 0x69 0x6a>;
		key_val = <0x00 0x8d 0x111 0x188>;
		key_tolerance = <0x28 0x28 0x28 0x28>;
	};

	unifykey {
		compatible = "amlogic, unifykey";
		status = "ok";
		unifykey-num = <0x0f>;
		unifykey-index-0 = <0x74>;
		unifykey-index-1 = <0x75>;
		unifykey-index-2 = <0x76>;
		unifykey-index-3 = <0x77>;
		unifykey-index-4 = <0x78>;
		unifykey-index-5 = <0x79>;
		unifykey-index-6 = <0x7a>;
		unifykey-index-7 = <0x7b>;
		unifykey-index-8 = <0x7c>;
		unifykey-index-9 = <0x7d>;
		unifykey-index-10 = <0x7e>;
		unifykey-index-11 = <0x7f>;
		unifykey-index-12 = <0x80>;
		unifykey-index-13 = <0x81>;
		unifykey-index-14 = <0x82>;

		key_0 {
			key-name = "usid";
			key-device = "normal";
			key-permit = "read\0write\0del";
			linux,phandle = <0x74>;
			phandle = <0x74>;
		};

		key_1 {
			key-name = "mac";
			key-device = "normal";
			key-permit = "read\0write\0del";
			linux,phandle = <0x75>;
			phandle = <0x75>;
		};

		key_2 {
			key-name = "hdcp";
			key-device = "secure";
			key-type = "sha1";
			key-permit = "read\0write\0del";
			linux,phandle = <0x76>;
			phandle = <0x76>;
		};

		key_3 {
			key-name = "secure_boot_set";
			key-device = "efuse";
			key-permit = "write";
			linux,phandle = <0x77>;
			phandle = <0x77>;
		};

		key_4 {
			key-name = "mac_bt";
			key-device = "normal";
			key-permit = "read\0write\0del";
			key-type = "mac";
			linux,phandle = <0x78>;
			phandle = <0x78>;
		};

		key_5 {
			key-name = "mac_wifi";
			key-device = "normal";
			key-permit = "read\0write\0del";
			key-type = "mac";
			linux,phandle = <0x79>;
			phandle = <0x79>;
		};

		key_6 {
			key-name = "hdcp2_tx";
			key-device = "normal";
			key-permit = "read\0write\0del";
			linux,phandle = <0x7a>;
			phandle = <0x7a>;
		};

		key_7 {
			key-name = "hdcp2_rx";
			key-device = "normal";
			key-permit = "read\0write\0del";
			linux,phandle = <0x7b>;
			phandle = <0x7b>;
		};

		key_8 {
			key-name = "widevinekeybox";
			key-device = "secure";
			key-permit = "read\0write\0del";
			linux,phandle = <0x7c>;
			phandle = <0x7c>;
		};

		key_9 {
			key-name = "deviceid";
			key-device = "normal";
			key-permit = "read\0write\0del";
			linux,phandle = <0x7d>;
			phandle = <0x7d>;
		};

		key_10 {
			key-name = "hdcp22_fw_private";
			key-device = "secure";
			key-permit = "read\0write\0del";
			linux,phandle = <0x7e>;
			phandle = <0x7e>;
		};

		key_11 {
			key-name = "PlayReadykeybox25";
			key-device = "secure";
			key-permit = "read\0write\0del";
			linux,phandle = <0x7f>;
			phandle = <0x7f>;
		};

		key_12 {
			key-name = "prpubkeybox";
			key-device = "secure";
			key-permit = "read\0write\0del";
			linux,phandle = <0x80>;
			phandle = <0x80>;
		};

		key_13 {
			key-name = "prprivkeybox";
			key-device = "secure";
			key-permit = "read\0write\0del";
			linux,phandle = <0x81>;
			phandle = <0x81>;
		};

		key_14 {
			key-name = "attestationkeybox";
			key-device = "secure";
			key-permit = "read\0write\0del";
			linux,phandle = <0x82>;
			phandle = <0x82>;
		};
	};

	efusekey {
		keynum = <0x04>;
		key0 = <0x83>;
		key1 = <0x84>;
		key2 = <0x85>;
		key3 = <0x86>;

		key_0 {
			keyname = "mac";
			offset = <0x00>;
			size = <0x06>;
			linux,phandle = <0x83>;
			phandle = <0x83>;
		};

		key_1 {
			keyname = "mac_bt";
			offset = <0x06>;
			size = <0x06>;
			linux,phandle = <0x84>;
			phandle = <0x84>;
		};

		key_2 {
			keyname = "mac_wifi";
			offset = <0x0c>;
			size = <0x06>;
			linux,phandle = <0x85>;
			phandle = <0x85>;
		};

		key_3 {
			keyname = "usid";
			offset = <0x12>;
			size = <0x10>;
			linux,phandle = <0x86>;
			phandle = <0x86>;
		};
	};

	amlvecm {
		compatible = "amlogic, vecm";
		dev_name = "aml_vecm";
		status = "okay";
		gamma_en = <0x00>;
		wb_en = <0x00>;
		cm_en = <0x00>;
	};

	amdolby_vision {
		compatible = "amlogic, dolby_vision_g12a";
		dev_name = "aml_amdolby_vision_driver";
		status = "okay";
		tv_mode = <0x00>;
	};

	dummy {
		#sound-dai-cells = <0x00>;
		compatible = "amlogic, aml_dummy_codec";
		status = "okay";
		linux,phandle = <0x8b>;
		phandle = <0x8b>;
	};

	eqdrc {
		eqdrc_module = <0x01>;
		lane_mask = <0x01>;
		channel_mask = <0x03>;
		linux,phandle = <0x89>;
		phandle = <0x89>;
	};

	auge_sound {
		compatible = "amlogic, g12a-sound-card";
		aml-audio-card,name = "AML-AUGESOUND";
		aml-audio-card,loopback = <0x87>;
		avout_mute-gpios = <0x88 0x02 0x00>;
		aml-audio-card,effect = <0x89>;

		aml-audio-card,dai-link@0 {
			format = "dsp_a";
			mclk-fs = <0x200>;
			suffix-name = "alsaPORT-pcm";

			cpu {
				sound-dai = <0x8a>;
				dai-tdm-slot-tx-mask = <0x01 0x01 0x01 0x01 0x01 0x01 0x01 0x01>;
				dai-tdm-slot-rx-mask = <0x01 0x01 0x01 0x01 0x01 0x01 0x01 0x01>;
				dai-tdm-slot-num = <0x08>;
				dai-tdm-slot-width = <0x20>;
				system-clock-frequency = <0x1770000>;
			};

			codec {
				sound-dai = <0x8b 0x8b>;
			};
		};

		aml-audio-card,dai-link@1 {
			format = "i2s";
			mclk-fs = <0x100>;
			bitclock-master = <0x8c>;
			frame-master = <0x8c>;
			suffix-name = "alsaPORT-i2s";

			cpu {
				sound-dai = <0x8c>;
				dai-tdm-slot-tx-mask = <0x01 0x01>;
				dai-tdm-slot-rx-mask = <0x01 0x01>;
				dai-tdm-slot-num = <0x02>;
				dai-tdm-slot-width = <0x20>;
				system-clock-frequency = <0xbb8000>;
			};

			codec {
				sound-dai = <0x8b>;
			};
		};

		aml-audio-card,dai-link@2 {
			format = "i2s";
			mclk-fs = <0x100>;
			bitclock-master = <0x8d>;
			frame-master = <0x8d>;

			cpu {
				sound-dai = <0x8e>;
				dai-tdm-slot-tx-mask = <0x01 0x01>;
				dai-tdm-slot-rx-mask = <0x01 0x01>;
				dai-tdm-slot-num = <0x02>;
				dai-tdm-slot-width = <0x20>;
				system-clock-frequency = <0xbb8000>;
			};

			codec {
				sound-dai = <0x8b>;
				linux,phandle = <0x8d>;
				phandle = <0x8d>;
			};
		};

		aml-audio-card,dai-link@5 {
			mclk-fs = <0x80>;
			suffix-name = "alsaPORT-spdif";

			cpu {
				sound-dai = <0x8f>;
				system-clock-frequency = <0x5dc000>;
			};

			codec {
				sound-dai = <0x8b>;
			};
		};
	};

	cpu_opp_table0 {
		compatible = "operating-points-v2";
		opp-shared;
		linux,phandle = <0x19>;
		phandle = <0x19>;

		opp00 {
			opp-hz = <0x00 0x5f5e100>;
			opp-microvolt = <0xb9ca8>;
		};

		opp01 {
			opp-hz = <0x00 0xee6b280>;
			opp-microvolt = <0xb9ca8>;
		};

		opp02 {
			opp-hz = <0x00 0x1dcd6500>;
			opp-microvolt = <0xb9ca8>;
		};

		opp03 {
			opp-hz = <0x00 0x27c19cc0>;
			opp-microvolt = <0xb9ca8>;
		};

		opp04 {
			opp-hz = <0x00 0x3b9aca00>;
			opp-microvolt = <0xb9ca8>;
		};

		opp05 {
			opp-hz = <0x00 0x47868c00>;
			opp-microvolt = <0xb9ca8>;
		};

		opp06 {
			opp-hz = <0x00 0x5353c980>;
			opp-microvolt = <0xc11d8>;
		};

		opp07 {
			opp-hz = <0x00 0x5a1f4a00>;
			opp-microvolt = <0xcae18>;
		};

		opp08 {
			opp-hz = <0x00 0x5fd82200>;
			opp-microvolt = <0xd2348>;
		};

		opp09 {
			opp-hz = <0x00 0x6590fa00>;
			opp-microvolt = <0xd9878>;
		};
	};

	cpu_opp_table1 {
		compatible = "operating-points-v2";
		opp-shared;
		linux,phandle = <0x1d>;
		phandle = <0x1d>;

		opp00 {
			opp-hz = <0x00 0x5f5e100>;
			opp-microvolt = <0xb7598>;
		};

		opp01 {
			opp-hz = <0x00 0xee6b280>;
			opp-microvolt = <0xb7598>;
		};

		opp02 {
			opp-hz = <0x00 0x1dcd6500>;
			opp-microvolt = <0xb7598>;
		};

		opp03 {
			opp-hz = <0x00 0x27c19cc0>;
			opp-microvolt = <0xb7598>;
		};

		opp04 {
			opp-hz = <0x00 0x3b9aca00>;
			opp-microvolt = <0xbc3b8>;
		};

		opp05 {
			opp-hz = <0x00 0x47868c00>;
			opp-microvolt = <0xbc3b8>;
		};

		opp06 {
			opp-hz = <0x00 0x5353c980>;
			opp-microvolt = <0xc11d8>;
		};

		opp07 {
			opp-hz = <0x00 0x5a1f4a00>;
			opp-microvolt = <0xc8708>;
		};

		opp08 {
			opp-hz = <0x00 0x5fd82200>;
			opp-microvolt = <0xd2348>;
		};

		opp09 {
			opp-hz = <0x00 0x6590fa00>;
			opp-microvolt = <0xd9878>;
		};
	};

	cpufreq-meson {
		compatible = "amlogic, cpufreq-meson";
		status = "okay";
	};

	thermistor0 {
		compatible = "amlogic,thermistor";
		status = "okay";
		pull_up_resistor = <0x9858>;
		over_critical_low = <0x2fc44>;
		pull_up_voltage = <0x708>;
		ntc_table = <0x07>;
		adc_channel = <0x00>;
	};

	thermistor1 {
		compatible = "amlogic,thermistor";
		status = "okay";
		pull_up_resistor = <0x9858>;
		over_critical_low = <0x2fc44>;
		pull_up_voltage = <0x708>;
		ntc_table = <0x07>;
		adc_channel = <0x01>;
	};

	virtual-sensor {
		compatible = "amazon,virtual_sensor";
		#thermal-sensor-cells = <0x00>;
		linux,phandle = <0x68>;
		phandle = <0x68>;

		vs_components {

			vs_thermistor0 {
				vs_name = "thermistor0";
				offset = <0x64>;
				alpha = <0x0a>;
				weight = <0xaf>;
			};

			vs_thermistor1 {
				vs_name = "thermistor1";
				offset = <0xc8>;
				alpha = <0x14>;
				weight = <0x113>;
			};
		};

		cooling_devices {

			wificool {
				min_state = <0x00>;
				node_name = "wifi_cool";
				device_type = "wifi";
			};
		};

		wifi_cool {
			#cooling-cells = <0x02>;
			linux,phandle = <0x6d>;
			phandle = <0x6d>;
		};
	};
};
